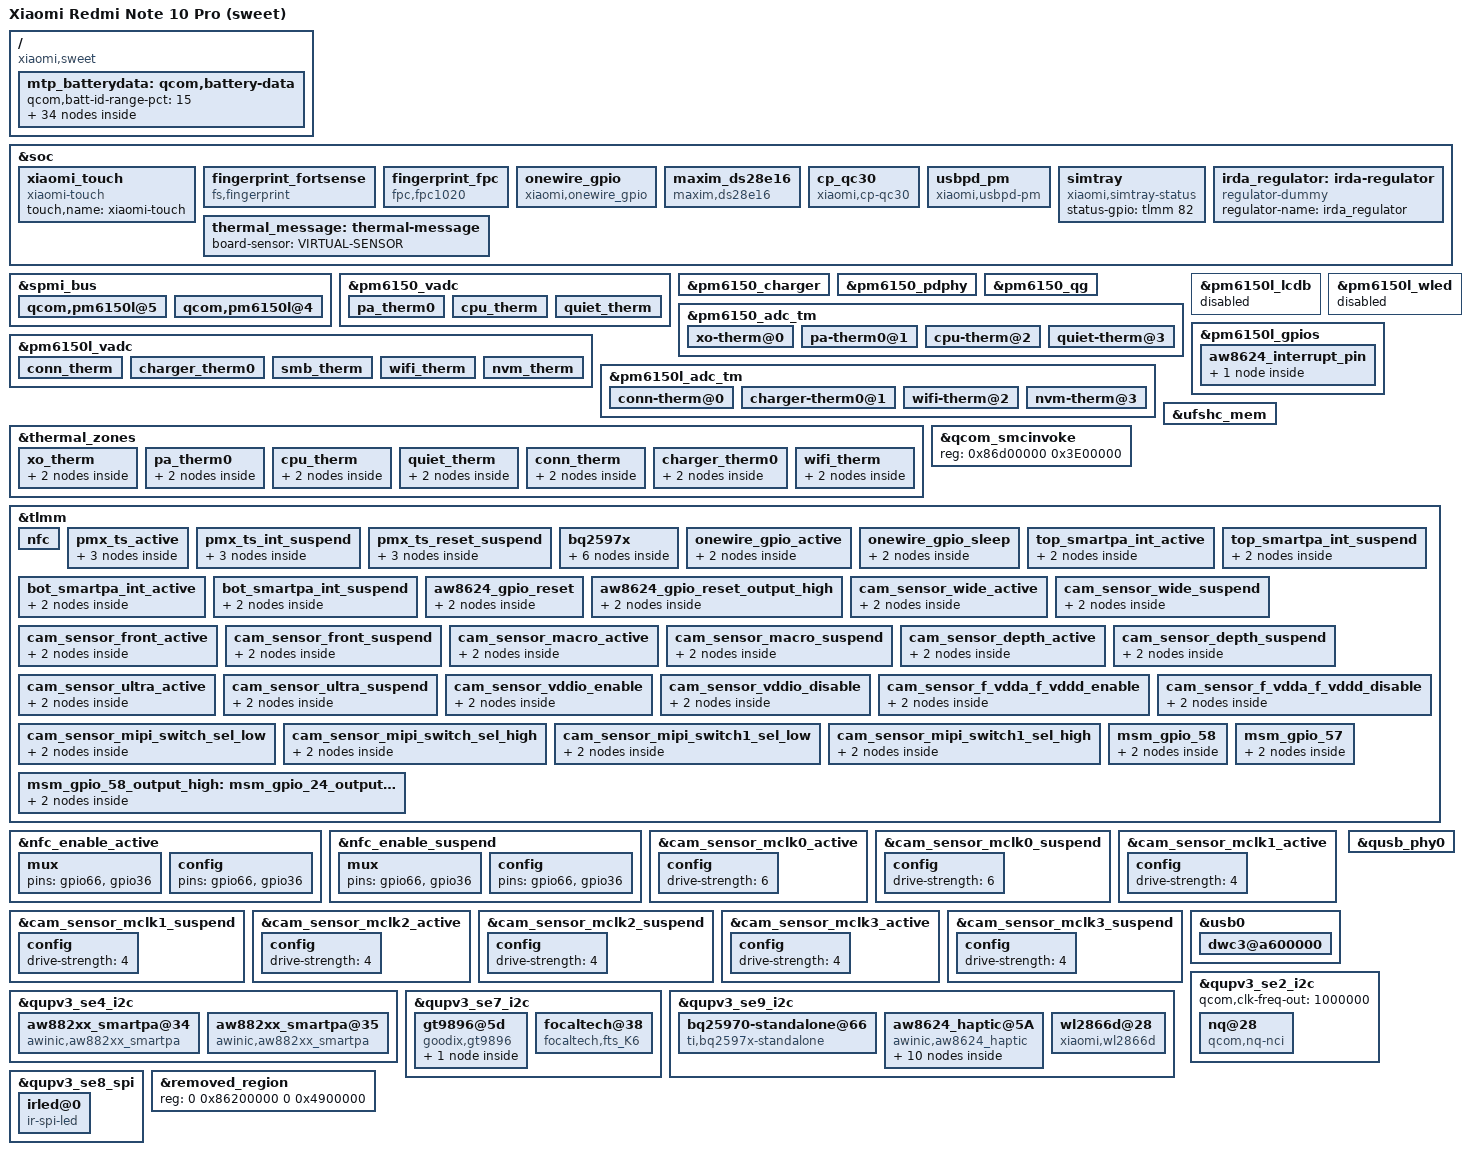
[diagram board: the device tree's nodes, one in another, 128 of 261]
/dts-v1/;

/* Generated by dtsplit.py (tools-sdmmagpie) from the 4.14 sweet files and the 6.1 violet DT. */

#include "xiaomi-sdmmagpie-common.dtsi"

/ {
	/* MERGE model: 4.14 target has "SWEET" */
	/* MERGE compatible: 4.14 target has "qcom,sdmmagpie-qrd", "qcom,sdmmagpie", "qcom,qrd" */
	model = "Xiaomi Redmi Note 10 Pro (sweet)";
	compatible = "xiaomi,sweet", "qcom,sdmmagpie";
	qcom,board-id = <46 0>;

	/* sweet battery profiles (4.14 sweet-sdmmagpie.dtsi) */
	mtp_batterydata: qcom,battery-data {
		qcom,batt-id-range-pct = <15>;

		qcom,04890898_xiaomi_K6_SWBN53_5020mah_FG {
			qcom,max-voltage-uv = <4450000>;
			qcom,ffc-max-voltage-uv = <4470000>;
			qcom,fg-cc-cv-threshold-uv = <4440000>;
			qcom,fastchg-current-ma = <6000>;
			qcom,jeita-fcc-ranges = <0 50 980000 51 100 2460000 101 150 3440000 151 480 6000000 481 600 2460000>;
			qcom,jeita-fv-ranges = <0 50 4450000 51 100 4450000 101 150 4450000 151 480 4470000 481 600 4100000>;
			qcom,step-chg-ranges = <3001000 4250000 6000000 4250001 4350000 4900000 4350001 4450000 4900000 4450001 4460000 3900000 4460001 4470000 3900000>;
			qcom,nom-batt-capacity-mah = <5020>;
			qcom,batt-id-kohm = <100>;
			qcom,battery-beta = <4250>;
			qcom,battery-therm-kohm = <100>;
			qcom,battery-type = "K6_sunwoda_5020mah";
			qcom,qg-batt-profile-ver = <100>;
			mi,six-pin-battery;
			mi,use-bq-pump;
			mi,step-chg-hysteresis = <5000>;

			qcom,fcc1-temp-lut {
				qcom,lut-col-legend = <0 10 25 40 50>;
				qcom,lut-data = <4757 4891 4997 5055 5078>;
			};

			qcom,fcc2-temp-lut {
				qcom,lut-col-legend = <(-10) 0 10 25 40 50>;
				qcom,lut-data = <4968 4967 5004 5018 5018 5015>;
			};

			qcom,pc-temp-v1-lut {
				qcom,lut-col-legend = <0 10 25 40 50>;
				qcom,lut-row-legend = <10000 9800 9600 9400 9200>, <9000 8800 8600 8400 8200>, <8000 7800 7600 7400 7200>, <7000 6800 6600 6400 6200>, <6000 5800 5600 5400 5200>, <5000 4800 4600 4400 4200>, <4000 3800 3600 3400 3200>, <3000 2800 2600 2400 2200>, <2000 1800 1600 1400 1200>, <1000 900 800 700 600>, <500 400 300 200 100>, <0>;
				qcom,lut-data = <44123 44255 44335 44363 44372>, <43931 44073 44168 44204 44214>, <43728 43883 43990 44030 44042>, <43515 43686 43802 43846 43859>, <43289 43478 43604 43651 43667>, <43055 43250 43393 43444 43463>, <42819 43012 43164 43222 43245>, <42578 42773 42925 42984 43012>, <42339 42529 42684 42743 42771>, <42102 42287 42438 42498 42528>, <41870 42049 42194 42253 42282>, <41643 41813 41951 42011 42040>, <41421 41583 41713 41772 41800>, <41206 41357 41480 41537 41564>, <41001 41137 41253 41305 41332>, <40803 40929 41033 41079 41105>, <40600 40727 40819 40860 40885>, <40386 40528 40611 40649 40671>, <40177 40340 40414 40446 40465>, <39990 40138 40230 40258 40274>, <39824 39879 40021 40062 40082>, <39642 39574 39731 39812 39844>, <39397 39337 39435 39523 39560>, <39137 39172 39244 39303 39330>, <38966 39038 39106 39150 39172>, <38857 38927 38982 39018 39038>, <38771 38834 38865 38887 38902>, <38696 38747 38756 38763 38771>, <38633 38661 38652 38650 38654>, <38573 38578 38551 38547 38553>, <38513 38500 38459 38453 38460>, <38456 38426 38377 38369 38372>, <38404 38359 38302 38293 38289>, <38355 38303 38234 38220 38209>, <38310 38254 38172 38149 38132>, <38268 38205 38115 38079 38056>, <38229 38161 38063 38014 37979>, <38177 38111 38011 37949 37901>, <38096 38034 37937 37867 37810>, <37993 37930 37833 37759 37699>, <37877 37813 37715 37637 37573>, <37737 37677 37586 37501 37429>, <37579 37525 37445 37354 37274>, <37404 37345 37280 37195 37114>, <37310 37215 37153 37077 37010>, <37223 37142 37078 37015 36950>, <37190 37123 37057 36994 36929>, <37160 37097 37042 36977 36914>, <37123 37067 37012 36942 36865>, <37016 36929 36885 36758 36651>, <36677 36555 36525 36382 36267>, <36194 36059 36046 35890 35773>, <35582 35420 35428 35255 35133>, <34752 34540 34583 34385 34252>, <33439 33113 33256 32985 32824>, <30000 30000 30000 30000 30000>;
			};

			qcom,pc-temp-v2-lut {
				qcom,lut-col-legend = <(-10) 0 10 25 40 50>;
				qcom,lut-row-legend = <10000 9800 9600 9400 9200 9000>, <8800 8600 8400 8200 8000 7800>, <7600 7400 7200 7000 6800 6600>, <6400 6200 6000 5800 5600 5400>, <5200 5000 4800 4600 4400 4200>, <4000 3800 3600 3400 3200 3000>, <2800 2600 2400 2200 2000 1800>, <1600 1400 1200 1000 900 800>, <700 600 500 400 300 200>, <100 0>;
				qcom,lut-data = <44365 44345 44335 44330 44290 44270>, <44073 44080 44114 44124 44081 44062>, <43806 43830 43898 43919 43873 43855>, <43569 43600 43687 43715 43668 43650>, <43363 43390 43485 43514 43465 43448>, <43153 43176 43274 43304 43255 43238>, <42920 42937 43041 43076 43028 43012>, <42676 42687 42796 42836 42791 42777>, <42428 42434 42551 42595 42552 42539>, <42172 42175 42303 42349 42307 42294>, <41922 41925 42057 42103 42064 42051>, <41689 41696 41814 41861 41823 41810>, <41466 41478 41575 41620 41584 41573>, <41248 41258 41341 41385 41351 41340>, <41041 41035 41111 41156 41123 41112>, <40815 40815 40890 40932 40901 40890>, <40509 40604 40686 40715 40685 40676>, <40151 40395 40485 40503 40474 40467>, <39863 40158 40257 40297 40272 40267>, <39643 39870 39993 40100 40082 40078>, <39440 39583 39731 39886 39876 39874>, <39231 39336 39487 39617 39611 39613>, <39025 39111 39256 39334 39330 39335>, <38833 38912 39062 39121 39119 39126>, <38649 38737 38896 38952 38954 38962>, <38484 38577 38748 38806 38809 38817>, <38343 38414 38613 38676 38680 38685>, <38217 38256 38490 38561 38564 38566>, <38125 38136 38377 38450 38456 38457>, <38062 38045 38273 38345 38355 38357>, <38009 37975 38176 38248 38263 38264>, <37955 37928 38082 38159 38180 38179>, <37903 37893 37995 38078 38102 38099>, <37847 37858 37917 38003 38017 38009>, <37789 37821 37846 37934 37929 37911>, <37727 37780 37784 37861 37833 37807>, <37661 37727 37733 37770 37726 37689>, <37591 37659 37688 37672 37613 37564>, <37512 37580 37625 37578 37510 37456>, <37414 37485 37536 37488 37416 37362>, <37309 37376 37430 37390 37316 37262>, <37211 37256 37302 37276 37200 37143>, <37115 37122 37160 37152 37077 37017>, <37028 37010 37026 37014 36942 36878>, <36947 36911 36924 36926 36865 36806>, <36859 36810 36861 36887 36838 36781>, <36807 36748 36830 36873 36826 36768>, <36742 36670 36791 36851 36802 36742>, <36646 36565 36715 36802 36737 36655>, <36481 36407 36531 36631 36462 36340>, <36210 36170 36160 36217 36014 35882>, <35788 35773 35605 35676 35440 35296>, <35176 35186 34846 34962 34686 34517>, <34277 34354 33804 33970 33604 33420>, <32804 32994 31968 32363 31950 31600>, <28324 29464 26656 28793 27050 26674>;
			};

			qcom,pc-temp-z1-lut {
				qcom,lut-col-legend = <0 10 25 40 50>;
				qcom,lut-row-legend = <10000 9800 9600 9400 9200>, <9000 8800 8600 8400 8200>, <8000 7800 7600 7400 7200>, <7000 6800 6600 6400 6200>, <6000 5800 5600 5400 5200>, <5000 4800 4600 4400 4200>, <4000 3800 3600 3400 3200>, <3000 2800 2600 2400 2200>, <2000 1800 1600 1400 1200>, <1000 900 800 700 600>, <500 400 300 200 100>, <0>;
				qcom,lut-data = <12324 11754 11200 10935 10845>, <12334 11788 11232 10974 10885>, <12340 11798 11251 10987 10898>, <12343 11797 11254 10990 10904>, <12344 11792 11250 10989 10904>, <12343 11780 11245 10986 10902>, <12341 11764 11238 10982 10900>, <12339 11751 11228 10978 10897>, <12334 11738 11220 10975 10895>, <12302 11726 11211 10973 10895>, <12260 11713 11206 10971 10895>, <12243 11700 11203 10970 10894>, <12236 11696 11201 10969 10894>, <12229 11694 11200 10968 10893>, <12215 11693 11199 10968 10893>, <12198 11691 11199 10968 10894>, <12185 11689 11198 10969 10894>, <12171 11687 11198 10969 10896>, <12160 11680 11198 10969 10897>, <12158 11673 11199 10970 10898>, <12158 11673 11199 10970 10899>, <12159 11675 11199 10971 10900>, <12160 11677 11200 10971 10900>, <12164 11683 11201 10972 10901>, <12166 11689 11203 10973 10903>, <12164 11689 11205 10975 10906>, <12164 11687 11208 10978 10908>, <12171 11685 11211 10981 10911>, <12180 11688 11215 10984 10914>, <12186 11692 11219 10987 10916>, <12186 11694 11223 10991 10919>, <12186 11696 11227 10994 10922>, <12188 11699 11231 10997 10926>, <12199 11703 11236 11001 10930>, <12210 11708 11242 11006 10933>, <12215 11713 11247 11010 10937>, <12217 11717 11251 11014 10941>, <12218 11723 11254 11018 10944>, <12235 11733 11259 11021 10948>, <12256 11750 11267 11025 10951>, <12261 11762 11273 11029 10953>, <12266 11769 11278 11032 10956>, <12275 11780 11282 11034 10958>, <12297 11806 11288 11037 10960>, <12318 11806 11299 11042 10963>, <12300 11798 11304 11045 10965>, <12309 11804 11304 11045 10965>, <12302 11800 11302 11046 10967>, <12292 11794 11304 11048 10969>, <12315 11799 11316 11054 10973>, <12330 11819 11321 11058 10977>, <12351 11835 11328 11065 10983>, <12575 11865 11334 11071 10989>, <12356 11859 11348 11083 11000>, <12356 11859 11348 11083 11000>, <12356 11859 11348 11083 11000>;
			};

			qcom,pc-temp-z2-lut {
				qcom,lut-col-legend = <0 10 25 40 50>;
				qcom,lut-row-legend = <10000 9800 9600 9400 9200>, <9000 8800 8600 8400 8200>, <8000 7800 7600 7400 7200>, <7000 6800 6600 6400 6200>, <6000 5800 5600 5400 5200>, <5000 4800 4600 4400 4200>, <4000 3800 3600 3400 3200>, <3000 2800 2600 2400 2200>, <2000 1800 1600 1400 1200>, <1000 900 800 700 600>, <500 400 300 200 100>, <0>;
				qcom,lut-data = <11147 10298 10813 10403 10266>, <10909 10780 10834 10509 10460>, <10730 10802 10841 10581 10424>, <10641 10776 10830 10608 10395>, <10587 10745 10783 10583 10386>, <10546 10700 10731 10541 10371>, <10512 10653 10678 10508 10361>, <10483 10620 10628 10477 10344>, <10468 10592 10591 10453 10329>, <10462 10580 10560 10436 10325>, <10458 10581 10549 10422 10322>, <10460 10583 10571 10410 10296>, <10477 10592 10604 10400 10201>, <10501 10637 10622 10389 10144>, <10532 10684 10634 10364 10148>, <10574 10707 10648 10342 10156>, <10614 10726 10669 10328 10168>, <10655 10745 10693 10294 10193>, <10690 10771 10714 10288 10221>, <10715 10788 10733 10312 10250>, <10735 10788 10758 10353 10280>, <10744 10784 10810 10461 10315>, <10729 10776 10861 10650 10353>, <10700 10745 10850 10706 10389>, <10688 10713 10779 10587 10416>, <10685 10721 10740 10473 10444>, <10683 10768 10820 10562 10491>, <10688 10808 10927 10785 10555>, <10706 10831 10937 10848 10572>, <10723 10847 10906 10706 10420>, <10736 10845 10868 10550 10242>, <10747 10823 10810 10486 10188>, <10757 10805 10755 10442 10151>, <10765 10802 10749 10420 10147>, <10774 10800 10761 10433 10194>, <10786 10802 10779 10463 10264>, <10801 10817 10820 10539 10334>, <10820 10841 10879 10671 10414>, <10853 10875 10938 10754 10475>, <10893 10921 11007 10816 10516>, <10932 10955 11045 10862 10563>, <10970 10972 11050 10890 10673>, <11044 10998 11054 10907 10788>, <11164 11062 11066 10897 10808>, <11003 11393 11124 10779 10686>, <10822 11490 11148 10618 10471>, <10770 11534 11095 10612 10452>, <10764 11519 11081 10613 10484>, <10775 11621 11133 10758 10636>, <10709 11763 11195 10695 10552>, <10682 11824 11088 10412 10256>, <10511 11686 10933 10331 10191>, <10398 11512 10852 10258 10146>, <10181 11221 10771 10226 10062>, <10181 11221 10771 10226 10062>, <10181 11221 10771 10226 10062>;
			};

			qcom,pc-temp-z3-lut {
				qcom,lut-col-legend = <0 10 25 40 50>;
				qcom,lut-row-legend = <10000 9800 9600 9400 9200>, <9000 8800 8600 8400 8200>, <8000 7800 7600 7400 7200>, <7000 6800 6600 6400 6200>, <6000 5800 5600 5400 5200>, <5000 4800 4600 4400 4200>, <4000 3800 3600 3400 3200>, <3000 2800 2600 2400 2200>, <2000 1800 1600 1400 1200>, <1000 900 800 700 600>, <500 400 300 200 100>, <0>;
				qcom,lut-data = <19535 19404 19340 19325 19325>, <19607 19476 19387 19345 19335>, <19665 19515 19422 19374 19358>, <19702 19542 19439 19394 19380>, <19729 19562 19450 19404 19389>, <19749 19579 19457 19412 19395>, <19764 19590 19464 19420 19402>, <19777 19591 19469 19428 19409>, <19784 19590 19469 19431 19412>, <19789 19588 19468 19428 19411>, <19793 19585 19466 19422 19407>, <19792 19579 19459 19416 19403>, <19787 19572 19450 19408 19396>, <19780 19561 19441 19401 19390>, <19771 19551 19432 19396 19386>, <19759 19546 19425 19392 19382>, <19749 19542 19421 19388 19379>, <19741 19537 19418 19384 19376>, <19733 19528 19415 19380 19373>, <19728 19522 19411 19375 19368>, <19724 19536 19409 19372 19364>, <19722 19577 19424 19374 19363>, <19737 19593 19444 19379 19364>, <19762 19574 19440 19380 19364>, <19768 19546 19411 19363 19359>, <19757 19530 19395 19347 19353>, <19742 19517 19395 19366 19366>, <19730 19511 19395 19412 19408>, <19717 19518 19402 19428 19426>, <19710 19530 19428 19426 19416>, <19707 19540 19444 19422 19402>, <19705 19550 19445 19415 19393>, <19703 19556 19445 19403 19386>, <19701 19553 19442 19392 19378>, <19698 19548 19435 19384 19369>, <19694 19544 19428 19377 19361>, <19689 19540 19420 19373 19358>, <19683 19536 19413 19369 19355>, <19675 19531 19411 19367 19354>, <19665 19524 19409 19366 19353>, <19655 19517 19409 19365 19353>, <19644 19512 19410 19374 19363>, <19627 19505 19410 19385 19379>, <19596 19494 19405 19383 19380>, <19344 19446 19384 19371 19369>, <19305 19424 19374 19344 19344>, <19298 19410 19373 19342 19340>, <19295 19410 19362 19340 19330>, <19294 19367 19355 19325 19322>, <19293 19383 19349 19341 19334>, <19297 19306 19356 19364 19360>, <19297 19301 19346 19367 19360>, <19299 19297 19343 19369 19362>, <19304 19290 19344 19357 19360>, <19304 19290 19344 19357 19360>, <19304 19290 19344 19357 19360>;
			};

			qcom,pc-temp-z4-lut {
				qcom,lut-col-legend = <0 10 25 40 50>;
				qcom,lut-row-legend = <10000 9800 9600 9400 9200>, <9000 8800 8600 8400 8200>, <8000 7800 7600 7400 7200>, <7000 6800 6600 6400 6200>, <6000 5800 5600 5400 5200>, <5000 4800 4600 4400 4200>, <4000 3800 3600 3400 3200>, <3000 2800 2600 2400 2200>, <2000 1800 1600 1400 1200>, <1000 900 800 700 600>, <500 400 300 200 100>, <0>;
				qcom,lut-data = <15538 15236 14999 14882 14826>, <15517 15308 14998 14890 14847>, <15484 15289 14996 14881 14843>, <15436 15206 14982 14869 14836>, <15341 15127 14939 14848 14822>, <15239 15065 14898 14822 14799>, <15164 15009 14867 14799 14779>, <15098 14964 14840 14776 14761>, <15042 14927 14817 14758 14745>, <14993 14895 14796 14741 14730>, <14951 14867 14779 14729 14719>, <14918 14843 14765 14725 14715>, <14891 14822 14754 14723 14714>, <14868 14803 14748 14720 14713>, <14845 14789 14745 14716 14709>, <14825 14778 14741 14711 14705>, <14815 14771 14734 14707 14700>, <14812 14769 14726 14702 14695>, <14809 14772 14723 14698 14691>, <14808 14779 14721 14696 14690>, <14806 14793 14721 14695 14689>, <14806 14823 14756 14717 14706>, <14832 14852 14810 14779 14771>, <14879 14886 14842 14816 14803>, <14897 14911 14866 14833 14803>, <14901 14913 14875 14842 14802>, <14902 14909 14868 14817 14782>, <14899 14902 14853 14753 14724>, <14885 14881 14830 14721 14698>, <14869 14851 14790 14711 14697>, <14853 14826 14760 14705 14696>, <14836 14803 14744 14702 14694>, <14821 14787 14733 14700 14689>, <14809 14780 14729 14699 14687>, <14799 14775 14728 14701 14689>, <14790 14772 14727 14702 14690>, <14782 14769 14728 14702 14691>, <14776 14768 14729 14702 14691>, <14773 14769 14732 14704 14693>, <14770 14772 14741 14715 14703>, <14763 14772 14746 14724 14711>, <14750 14760 14738 14714 14703>, <14738 14745 14727 14701 14690>, <14728 14734 14724 14701 14691>, <14864 14704 14707 14694 14686>, <14886 14685 14679 14684 14671>, <14885 14685 14667 14672 14662>, <14879 14674 14658 14656 14651>, <14877 14714 14653 14651 14640>, <14876 14700 14669 14659 14663>, <14885 14807 14691 14662 14662>, <14891 14815 14704 14663 14666>, <14894 14824 14710 14664 14666>, <14902 14834 14711 14676 14668>, <14902 14834 14711 14676 14668>, <14902 14834 14711 14676 14668>;
			};

			qcom,pc-temp-z5-lut {
				qcom,lut-col-legend = <0 10 25 40 50>;
				qcom,lut-row-legend = <10000 9800 9600 9400 9200>, <9000 8800 8600 8400 8200>, <8000 7800 7600 7400 7200>, <7000 6800 6600 6400 6200>, <6000 5800 5600 5400 5200>, <5000 4800 4600 4400 4200>, <4000 3800 3600 3400 3200>, <3000 2800 2600 2400 2200>, <2000 1800 1600 1400 1200>, <1000 900 800 700 600>, <500 400 300 200 100>, <0>;
				qcom,lut-data = <13138 12985 13500 13875 14350>, <14188 14730 15281 14900 14974>, <15064 15622 16528 16568 16703>, <15704 16188 17034 17785 18361>, <16151 16719 17308 18333 19126>, <16599 17280 17596 18800 19710>, <17197 17811 17962 19612 20554>, <17922 18291 18343 20794 21826>, <18741 18718 18705 21684 23014>, <19782 19193 19061 22330 24035>, <20934 19779 19446 22747 24854>, <22002 20452 19999 22594 24857>, <23080 21208 20452 21982 24146>, <24181 22098 20426 21619 23693>, <25218 22983 20150 21870 23812>, <26272 23907 20016 22240 24088>, <27706 24767 20581 22501 24565>, <30434 24946 21453 23140 25628>, <32812 24360 21919 23653 26449>, <33106 23805 22184 24222 26902>, <32880 30080 22714 24723 27195>, <32794 47031 27829 24897 26789>, <39083 53991 34105 24895 24828>, <49798 43999 32902 24375 22514>, <52398 30996 24374 20036 19181>, <46447 25969 18921 16014 16396>, <39443 23023 17913 17572 18649>, <35950 21945 17369 22105 26398>, <33330 22522 17830 24992 29633>, <32327 23813 20369 26763 28113>, <33013 25771 23079 27725 26472>, <34396 29549 25391 27389 26462>, <35900 32929 27534 26549 26917>, <37880 34851 29079 26204 26999>, <39817 36306 30405 26632 26536>, <41246 37130 30963 27048 26135>, <42463 37698 30497 27095 26369>, <43547 37989 29631 27053 26949>, <44647 37400 28840 26492 26904>, <45538 35880 27818 24714 24564>, <45911 34979 27295 23458 22578>, <45946 34505 27348 25800 26567>, <45435 34328 27397 28818 32474>, <42949 34226 26145 27919 32544>, <17074 33443 25068 25279 28665>, <13468 31192 25892 19940 20952>, <13204 26073 27431 20700 21130>, <13137 27849 26089 23250 21487>, <13108 22125 25989 21722 23386>, <13164 21237 21541 25221 24234>, <13244 13620 18391 23514 24384>, <13066 13274 16300 22702 22231>, <12952 12953 15517 21271 20649>, <12790 12581 15188 17110 17819>, <12790 12581 15188 17110 17819>, <12790 12581 15188 17110 17819>;
			};

			qcom,pc-temp-z6-lut {
				qcom,lut-col-legend = <0 10 25 40 50>;
				qcom,lut-row-legend = <10000 9800 9600 9400 9200>, <9000 8800 8600 8400 8200>, <8000 7800 7600 7400 7200>, <7000 6800 6600 6400 6200>, <6000 5800 5600 5400 5200>, <5000 4800 4600 4400 4200>, <4000 3800 3600 3400 3200>, <3000 2800 2600 2400 2200>, <2000 1800 1600 1400 1200>, <1000 900 800 700 600>, <500 400 300 200 100>, <0>;
				qcom,lut-data = <15508 14992 14667 14556 14518>, <15504 15059 14699 14580 14542>, <15492 15056 14716 14594 14556>, <15471 15027 14714 14598 14563>, <15422 14997 14702 14594 14561>, <15366 14969 14688 14588 14556>, <15324 14942 14677 14582 14552>, <15286 14916 14667 14577 14548>, <15252 14892 14656 14571 14544>, <15221 14871 14645 14562 14538>, <15193 14852 14635 14554 14531>, <15168 14835 14625 14547 14525>, <15146 14819 14615 14542 14521>, <15125 14803 14608 14537 14517>, <15103 14790 14601 14532 14513>, <15082 14782 14595 14528 14509>, <15067 14775 14589 14523 14505>, <15055 14771 14584 14518 14501>, <15047 14769 14581 14514 14497>, <15044 14767 14578 14511 14494>, <15042 14780 14577 14509 14491>, <15041 14816 14603 14521 14498>, <15061 14833 14637 14552 14527>, <15095 14834 14641 14563 14540>, <15105 14835 14640 14562 14539>, <15101 14833 14637 14560 14536>, <15096 14826 14633 14558 14534>, <15089 14818 14629 14556 14533>, <15078 14813 14625 14553 14531>, <15068 14808 14621 14549 14526>, <15060 14804 14617 14544 14519>, <15053 14800 14612 14538 14514>, <15047 14797 14608 14532 14509>, <15043 14794 14604 14527 14504>, <15039 14791 14601 14524 14500>, <15036 14790 14598 14522 14497>, <15033 14788 14595 14519 14495>, <15032 14788 14593 14516 14493>, <15034 14789 14593 14516 14493>, <15036 14791 14598 14520 14496>, <15036 14791 14600 14524 14500>, <15034 14787 14598 14525 14503>, <15031 14782 14595 14526 14506>, <15023 14777 14592 14525 14507>, <14967 14749 14576 14516 14499>, <14956 14731 14559 14498 14480>, <14952 14724 14554 14492 14475>, <14950 14721 14545 14484 14464>, <14953 14719 14539 14473 14455>, <14958 14727 14545 14486 14471>, <14970 14737 14560 14502 14488>, <14979 14742 14563 14506 14492>, <14989 14750 14567 14510 14496>, <15008 14760 14572 14512 14499>, <15008 14760 14572 14512 14499>, <15008 14760 14572 14512 14499>;
			};

			qcom,pc-temp-y1-lut {
				qcom,lut-col-legend = <(-10) 0 10 25 40 50>;
				qcom,lut-row-legend = <10000 9800 9600 9400 9200 9000>, <8800 8600 8400 8200 8000 7800>, <7600 7400 7200 7000 6800 6600>, <6400 6200 6000 5800 5600 5400>, <5200 5000 4800 4600 4400 4200>, <4000 3800 3600 3400 3200 3000>, <2800 2600 2400 2200 2000 1800>, <1600 1400 1200 1000 900 800>, <700 600 500 400 300 200>, <100 0>;
				qcom,lut-data = <5992 5573 5288 5013 4864 4813>, <5980 5573 5297 5013 4863 4813>, <5967 5573 5304 5012 4862 4812>, <5955 5574 5308 5010 4861 4812>, <5945 5575 5310 5009 4860 4811>, <5941 5576 5311 5007 4859 4810>, <5943 5579 5308 5004 4859 4810>, <5946 5583 5303 5002 4858 4809>, <5949 5584 5299 5000 4857 4809>, <5954 5578 5294 4998 4856 4808>, <5958 5573 5290 4997 4855 4808>, <5957 5573 5287 4996 4854 4807>, <5954 5574 5284 4996 4853 4807>, <5954 5573 5284 4995 4852 4806>, <5960 5567 5284 4993 4852 4806>, <5969 5562 5285 4992 4852 4806>, <5979 5572 5284 4992 4852 4805>, <5990 5591 5283 4992 4852 4805>, <5993 5597 5283 4993 4852 4805>, <5988 5586 5285 4994 4852 4806>, <5983 5577 5287 4995 4852 4807>, <5979 5577 5285 4996 4854 4808>, <5968 5579 5282 4996 4856 4808>, <5964 5579 5282 4997 4857 4809>, <5964 5581 5286 4999 4857 4811>, <5962 5583 5289 5002 4858 4812>, <5958 5582 5288 5003 4858 4813>, <5950 5577 5285 5005 4860 4815>, <5945 5572 5286 5007 4861 4816>, <5941 5573 5292 5009 4863 4818>, <5937 5575 5296 5012 4865 4820>, <5935 5573 5297 5013 4867 4821>, <5934 5568 5296 5014 4868 4822>, <5933 5566 5297 5016 4870 4823>, <5929 5569 5303 5018 4872 4824>, <5924 5572 5307 5020 4873 4826>, <5921 5569 5305 5021 4874 4827>, <5916 5560 5300 5021 4875 4828>, <5912 5553 5299 5022 4876 4829>, <5905 5548 5301 5025 4877 4831>, <5899 5543 5304 5027 4878 4832>, <5899 5542 5309 5029 4879 4833>, <5899 5544 5315 5032 4882 4835>, <5896 5546 5323 5035 4884 4837>, <5904 5549 5324 5040 4888 4839>, <5979 5564 5333 5045 4888 4840>, <5951 5571 5341 5044 4888 4840>, <5952 5581 5332 5048 4888 4840>, <5945 5587 5481 5042 4888 4841>, <5965 5588 5369 5042 4889 4841>, <5969 5590 5336 5048 4890 4843>, <5957 5583 5350 5052 4894 4847>, <5945 5585 5346 5059 4899 4851>, <6007 5593 5348 5069 4907 4859>, <6007 5593 5348 5069 4907 4859>, <6007 5593 5348 5069 4907 4859>;
			};

			qcom,pc-temp-y2-lut {
				qcom,lut-col-legend = <(-10) 0 10 25 40 50>;
				qcom,lut-row-legend = <10000 9800 9600 9400 9200 9000>, <8800 8600 8400 8200 8000 7800>, <7600 7400 7200 7000 6800 6600>, <6400 6200 6000 5800 5600 5400>, <5200 5000 4800 4600 4400 4200>, <4000 3800 3600 3400 3200 3000>, <2800 2600 2400 2200 2000 1800>, <1600 1400 1200 1000 900 800>, <700 600 500 400 300 200>, <100 0>;
				qcom,lut-data = <10597 10766 11398 11596 11200 11128>, <10630 10803 11387 11536 11142 11076>, <10709 10871 11372 11472 11082 11014>, <10803 10947 11354 11411 11024 10951>, <10883 11010 11334 11358 10973 10897>, <10919 11037 11311 11321 10933 10860>, <10919 11035 11280 11296 10899 10838>, <10919 11030 11250 11277 10872 10820>, <10919 11031 11241 11258 10859 10802>, <10921 11044 11237 11237 10852 10777>, <10925 11057 11236 11226 10847 10760>, <10957 11056 11250 11233 10843 10756>, <11022 11048 11282 11249 10838 10755>, <11076 11062 11315 11266 10852 10756>, <11140 11154 11351 11291 10929 10758>, <11187 11244 11394 11325 10989 10760>, <11200 11291 11463 11378 11001 10762>, <11209 11345 11537 11452 11010 10765>, <11221 11362 11565 11545 11063 10804>, <11246 11371 11576 11682 11262 10990>, <11274 11382 11581 11757 11389 11112>, <11295 11394 11586 11702 11342 11102>, <11313 11411 11598 11615 11262 11086>, <11317 11427 11610 11603 11237 11083>, <11287 11451 11634 11639 11235 11086>, <11238 11470 11657 11679 11248 11090>, <11075 11448 11672 11709 11310 11113>, <10719 11382 11687 11739 11397 11159>, <10527 11345 11710 11771 11426 11221>, <10189 11352 11752 11808 11422 11330>, <9834 11357 11779 11840 11431 11423>, <9767 11313 11757 11864 11522 11480>, <9741 11200 11712 11882 11641 11524>, <9721 11056 11692 11890 11671 11546>, <9703 10726 11686 11894 11675 11576>, <9690 10374 11678 11891 11673 11580>, <9683 10177 11641 11844 11569 11503>, <9679 9874 11565 11766 11411 11383>, <9675 9716 11486 11728 11385 11311>, <9672 9693 11401 11709 11413 11262>, <9670 9680 11303 11690 11431 11227>, <9668 9673 11180 11664 11403 11208>, <9667 9669 11041 11627 11342 11185>, <9666 9666 10901 11523 11174 11068>, <9664 9664 10767 11404 11005 10901>, <9663 9663 10778 11336 10983 10832>, <9662 9663 10771 11319 11048 10840>, <9662 9662 10738 11314 11086 10887>, <9661 9661 10723 11320 11144 10873>, <9659 9660 10708 11349 11003 10834>, <9658 9659 10638 11299 10876 10763>, <9656 9658 10491 11190 10825 10710>, <9653 9657 9948 11078 10781 10622>, <9650 9655 9722 10982 10651 10446>, <9650 9655 9722 10982 10651 10446>, <9650 9655 9722 10982 10651 10446>;
			};

			qcom,pc-temp-y3-lut {
				qcom,lut-col-legend = <(-10) 0 10 25 40 50>;
				qcom,lut-row-legend = <10000 9800 9600 9400 9200 9000>, <8800 8600 8400 8200 8000 7800>, <7600 7400 7200 7000 6800 6600>, <6400 6200 6000 5800 5600 5400>, <5200 5000 4800 4600 4400 4200>, <4000 3800 3600 3400 3200 3000>, <2800 2600 2400 2200 2000 1800>, <1600 1400 1200 1000 900 800>, <700 600 500 400 300 200>, <100 0>;
				qcom,lut-data = <13439 13416 13326 13287 13280 13279>, <13446 13419 13330 13289 13281 13279>, <13458 13422 13334 13291 13281 13280>, <13473 13425 13337 13292 13282 13280>, <13485 13427 13340 13294 13282 13281>, <13491 13429 13343 13295 13283 13282>, <13492 13430 13344 13295 13284 13283>, <13493 13431 13345 13296 13285 13284>, <13492 13432 13347 13297 13287 13285>, <13487 13432 13349 13298 13288 13285>, <13483 13432 13350 13298 13288 13285>, <13495 13439 13350 13298 13289 13286>, <13517 13451 13349 13298 13289 13287>, <13519 13450 13348 13299 13290 13288>, <13474 13410 13346 13303 13294 13289>, <13437 13377 13343 13305 13297 13290>, <13440 13385 13339 13304 13296 13291>, <13448 13405 13335 13303 13294 13292>, <13450 13411 13333 13304 13294 13293>, <13439 13398 13332 13306 13298 13295>, <13425 13383 13331 13308 13300 13296>, <13415 13375 13328 13304 13295 13291>, <13407 13369 13323 13296 13286 13284>, <13399 13362 13321 13292 13282 13282>, <13392 13356 13319 13289 13281 13281>, <13385 13350 13318 13288 13280 13281>, <13369 13346 13317 13289 13281 13280>, <13344 13343 13317 13290 13281 13280>, <13335 13339 13316 13290 13281 13281>, <13343 13328 13314 13289 13280 13282>, <13355 13320 13313 13289 13279 13282>, <13369 13321 13313 13289 13280 13282>, <13386 13331 13312 13289 13281 13281>, <13406 13340 13312 13289 13281 13282>, <13428 13348 13312 13290 13282 13282>, <13454 13357 13312 13290 13282 13283>, <13485 13372 13313 13290 13281 13282>, <13522 13395 13317 13289 13280 13280>, <13560 13422 13320 13289 13280 13280>, <13599 13454 13322 13289 13282 13281>, <13638 13493 13324 13289 13284 13282>, <13680 13537 13326 13289 13284 13282>, <13724 13588 13328 13289 13284 13282>, <13779 13649 13333 13289 13282 13279>, <13848 13724 13340 13292 13283 13280>, <13923 13794 13345 13297 13291 13288>, <13898 13747 13349 13302 13294 13290>, <13964 13799 13359 13306 13296 13291>, <14050 13848 13371 13309 13296 13290>, <14155 13908 13378 13308 13289 13285>, <14305 13965 13380 13301 13288 13285>, <14563 14041 13388 13305 13290 13288>, <15250 14208 13413 13308 13297 13294>, <17272 14524 13522 13319 13305 13303>, <17272 14524 13522 13319 13305 13303>, <17272 14524 13522 13319 13305 13303>;
			};

			qcom,pc-temp-y4-lut {
				qcom,lut-col-legend = <(-10) 0 10 25 40 50>;
				qcom,lut-row-legend = <10000 9800 9600 9400 9200 9000>, <8800 8600 8400 8200 8000 7800>, <7600 7400 7200 7000 6800 6600>, <6400 6200 6000 5800 5600 5400>, <5200 5000 4800 4600 4400 4200>, <4000 3800 3600 3400 3200 3000>, <2800 2600 2400 2200 2000 1800>, <1600 1400 1200 1000 900 800>, <700 600 500 400 300 200>, <100 0>;
				qcom,lut-data = <16736 16675 16565 16490 16464 16461>, <16778 16733 16596 16491 16465 16463>, <16855 16825 16632 16492 16468 16465>, <16942 16923 16665 16494 16470 16466>, <17015 17003 16689 16496 16472 16467>, <17051 17038 16699 16498 16473 16468>, <17056 17034 16695 16501 16474 16467>, <17058 17024 16686 16504 16475 16467>, <17061 17013 16680 16507 16476 16467>, <17065 16999 16676 16511 16478 16470>, <17068 16989 16674 16516 16481 16472>, <17052 16983 16678 16523 16485 16474>, <17023 16979 16687 16531 16490 16476>, <17027 16991 16698 16537 16493 16479>, <17139 17097 16716 16542 16494 16483>, <17232 17185 16739 16548 16495 16487>, <17145 17164 16779 16564 16504 16492>, <16946 17099 16822 16586 16519 16498>, <16864 17030 16823 16604 16535 16510>, <16848 16946 16768 16624 16557 16530>, <16834 16866 16706 16633 16568 16542>, <16811 16812 16657 16592 16542 16522>, <16778 16769 16615 16525 16499 16488>, <16744 16735 16594 16505 16483 16475>, <16699 16710 16582 16498 16478 16470>, <16668 16685 16576 16496 16476 16467>, <16678 16643 16574 16498 16478 16469>, <16712 16589 16573 16504 16482 16472>, <16736 16570 16573 16509 16488 16476>, <16750 16581 16575 16516 16498 16482>, <16763 16598 16576 16523 16509 16488>, <16774 16611 16571 16530 16518 16498>, <16784 16623 16560 16537 16526 16509>, <16795 16641 16553 16541 16526 16511>, <16808 16677 16546 16545 16523 16508>, <16819 16717 16542 16547 16518 16504>, <16824 16743 16549 16531 16506 16495>, <16827 16771 16565 16504 16490 16484>, <16828 16783 16579 16495 16483 16482>, <16824 16784 16589 16492 16479 16484>, <16819 16783 16599 16491 16477 16485>, <16819 16778 16610 16495 16476 16483>, <16823 16763 16620 16499 16476 16479>, <16832 16764 16625 16491 16462 16458>, <16857 16779 16636 16491 16462 16457>, <16886 16822 16626 16498 16486 16500>, <16851 16807 16636 16511 16516 16535>, <16868 16847 16669 16536 16549 16565>, <16885 16901 16707 16568 16566 16569>, <16896 16932 16730 16553 16495 16483>, <16896 16960 16715 16498 16475 16475>, <16887 16959 16712 16502 16479 16475>, <16948 16952 16773 16513 16479 16475>, <17582 16950 16862 16542 16507 16521>, <17582 16950 16862 16542 16507 16521>, <17582 16950 16862 16542 16507 16521>;
			};

			qcom,pc-temp-y5-lut {
				qcom,lut-col-legend = <(-10) 0 10 25 40 50>;
				qcom,lut-row-legend = <10000 9800 9600 9400 9200 9000>, <8800 8600 8400 8200 8000 7800>, <7600 7400 7200 7000 6800 6600>, <6400 6200 6000 5800 5600 5400>, <5200 5000 4800 4600 4400 4200>, <4000 3800 3600 3400 3200 3000>, <2800 2600 2400 2200 2000 1800>, <1600 1400 1200 1000 900 800>, <700 600 500 400 300 200>, <100 0>;
				qcom,lut-data = <12502 15656 18668 18954 18632 19508>, <13631 16121 18502 18462 18254 19032>, <14991 16578 18303 17976 17670 18585>, <16356 17005 18096 17495 17032 18200>, <17504 17377 17908 17020 16489 17911>, <18207 17670 17764 16551 16194 17752>, <18547 17919 17661 16063 16094 17758>, <18765 18111 17559 15597 16008 17811>, <18752 18125 17423 15241 15891 17631>, <18390 17959 17215 14955 15709 16880>, <18111 17831 16985 14673 15483 16241>, <19283 18413 16586 14288 15118 15985>, <21540 19536 16034 13942 14749 15804>, <21946 19592 15608 13932 14809 15694>, <20039 17364 15203 14194 15477 15759>, <18440 15491 14999 14365 15913 15835>, <19712 17553 15277 14164 15317 15660>, <22546 22098 15984 13848 14383 15419>, <23437 23491 17055 14204 14428 15561>, <22716 22807 19180 16540 15733 16095>, <21993 22180 20753 18489 16959 16753>, <21845 22271 21153 19194 17668 17668>, <21628 22581 21397 19638 18191 18574>, <21358 22773 21527 19498 18114 18691>, <20904 22886 21622 18386 17213 18376>, <20211 22970 21704 17648 16449 17948>, <18121 22813 21778 17989 16268 17191>, <14128 22145 21846 18526 16252 16350>, <12546 21161 21920 18543 16131 16216>, <12537 17691 22017 18056 15502 16352>, <12571 14339 22145 17734 15093 16461>, <12668 14259 22745 17876 15461 16449>, <12877 14920 23708 18230 16229 16469>, <13072 15387 23773 18827 16964 16928>, <13212 15397 22387 20119 17767 18559>, <13359 15269 21056 21138 18498 19638>, <13616 15102 20628 21582 19042 19597>, <14005 14585 20318 21869 19538 19480>, <14174 14305 19796 21649 20172 19692>, <13942 14291 18785 20119 20992 20937>, <13573 14279 17742 18727 21671 22391>, <13309 14210 16866 18099 22207 23927>, <13091 14060 16260 17700 22500 24925>, <13065 14011 16226 17497 19716 19136>, <13078 13961 16075 17255 16976 16903>, <13094 13588 16658 17197 17836 16776>, <13296 13796 16791 18041 17796 16271>, <13442 14017 17249 18525 17289 15973>, <13712 14337 18424 18759 17436 15758>, <13869 15426 19566 19371 17037 16788>, <14001 16296 19205 19446 16958 16357>, <13804 15589 17860 19866 16511 16385>, <12888 14114 14461 19649 19958 18394>, <10792 13215 13585 22446 24524 26331>, <10792 13215 13585 22446 24524 26331>, <10792 13215 13585 22446 24524 26331>;
			};

			qcom,pc-temp-y6-lut {
				qcom,lut-col-legend = <(-10) 0 10 25 40 50>;
				qcom,lut-row-legend = <10000 9800 9600 9400 9200 9000>, <8800 8600 8400 8200 8000 7800>, <7600 7400 7200 7000 6800 6600>, <6400 6200 6000 5800 5600 5400>, <5200 5000 4800 4600 4400 4200>, <4000 3800 3600 3400 3200 3000>, <2800 2600 2400 2200 2000 1800>, <1600 1400 1200 1000 900 800>, <700 600 500 400 300 200>, <100 0>;
				qcom,lut-data = <5609 5384 5142 5017 4986 4979>, <5621 5404 5153 5018 4987 4980>, <5636 5424 5163 5019 4988 4982>, <5651 5442 5171 5021 4989 4983>, <5662 5454 5176 5022 4990 4984>, <5667 5459 5178 5023 4992 4985>, <5666 5456 5176 5024 4993 4986>, <5663 5450 5172 5025 4994 4986>, <5660 5443 5169 5026 4995 4987>, <5655 5436 5167 5028 4996 4988>, <5652 5432 5166 5029 4997 4989>, <5654 5433 5167 5031 4999 4990>, <5657 5436 5167 5033 5000 4991>, <5661 5439 5168 5036 5002 4993>, <5667 5442 5171 5039 5004 4994>, <5671 5444 5174 5043 5007 4996>, <5653 5443 5182 5047 5010 4998>, <5610 5439 5191 5052 5012 5001>, <5589 5431 5191 5057 5017 5005>, <5581 5400 5175 5064 5025 5012>, <5574 5367 5156 5068 5030 5016>, <5566 5348 5140 5053 5018 5006>, <5557 5333 5125 5029 4999 4991>, <5549 5322 5118 5020 4992 4985>, <5540 5315 5114 5017 4990 4983>, <5534 5308 5112 5016 4989 4982>, <5533 5298 5112 5017 4989 4983>, <5536 5288 5112 5019 4991 4984>, <5540 5284 5113 5021 4993 4985>, <5556 5289 5114 5023 4995 4987>, <5581 5298 5114 5025 4998 4990>, <5605 5312 5113 5027 5001 4993>, <5632 5339 5112 5029 5004 4996>, <5663 5370 5111 5031 5005 4996>, <5697 5406 5111 5033 5004 4996>, <5735 5447 5111 5034 5003 4995>, <5774 5492 5116 5029 4999 4992>, <5817 5541 5127 5022 4993 4988>, <5858 5591 5137 5019 4993 4987>, <5895 5641 5148 5019 4993 4989>, <5932 5692 5160 5019 4993 4990>, <5973 5743 5175 5020 4994 4990>, <6016 5796 5194 5022 4994 4988>, <6070 5859 5217 5021 4989 4981>, <6140 5937 5247 5024 4990 4982>, <6220 6020 5246 5030 5003 5000>, <6210 5983 5253 5038 5014 5012>, <6272 6041 5279 5048 5024 5021>, <6351 6102 5307 5059 5030 5021>, <6449 6162 5325 5054 5004 4994>, <6582 6224 5334 5034 4998 4992>, <6805 6294 5371 5039 5002 4995>, <7419 6435 5466 5047 5008 5000>, <9235 6696 5634 5065 5023 5022>, <9235 6696 5634 5065 5023 5022>, <9235 6696 5634 5065 5023 5022>;
			};
		};

		qcom,4890802_xiaomi_K6_NVT_5020mAH_PM7150 {
			qcom,max-voltage-uv = <4450000>;
			qcom,ffc-max-voltage-uv = <4470000>;
			qcom,fg-cc-cv-threshold-uv = <4440000>;
			qcom,fastchg-current-ma = <6000>;
			qcom,jeita-fcc-ranges = <0 50 980000 51 100 2460000 101 150 3440000 151 480 6000000 481 600 2460000>;
			qcom,jeita-fv-ranges = <0 50 4450000 51 100 4450000 101 150 4450000 151 480 4470000 481 600 4100000>;
			qcom,step-chg-ranges = <3001000 4250000 6000000 4250001 4350000 4900000 4350001 4450000 4900000 4450001 4460000 3900000 4460001 4470000 3900000>;
			qcom,nom-batt-capacity-mah = <5020>;
			qcom,batt-id-kohm = <100>;
			qcom,battery-beta = <4250>;
			qcom,battery-therm-kohm = <100>;
			qcom,battery-type = "K6_nvt_5020mah";
			qcom,qg-batt-profile-ver = <100>;
			mi,six-pin-battery;
			mi,use-bq-pump;
			mi,step-chg-hysteresis = <5000>;

			qcom,fcc1-temp-lut {
				qcom,lut-col-legend = <0 10 25 40 50>;
				qcom,lut-data = <4813 4966 5078 5110 5119>;
			};

			qcom,fcc2-temp-lut {
				qcom,lut-col-legend = <(-10) 0 10 25 40 50>;
				qcom,lut-data = <4932 5013 5074 5084 5075 5068>;
			};

			qcom,pc-temp-v1-lut {
				qcom,lut-col-legend = <0 10 25 40 50>;
				qcom,lut-row-legend = <10000 9800 9600 9400 9200>, <9000 8800 8600 8400 8200>, <8000 7800 7600 7400 7200>, <7000 6800 6600 6400 6200>, <6000 5800 5600 5400 5200>, <5000 4800 4600 4400 4200>, <4000 3800 3600 3400 3200>, <3000 2800 2600 2400 2200>, <2000 1800 1600 1400 1200>, <1000 900 800 700 600>, <500 400 300 200 100>, <0>;
				qcom,lut-data = <44092 44235 44334 44366 44375>, <43867 44008 44099 44110 44113>, <43638 43781 43882 43894 43895>, <43406 43557 43666 43688 43693>, <43170 43333 43443 43472 43478>, <42930 43099 43216 43251 43257>, <42690 42857 42979 43021 43028>, <42449 42612 42733 42779 42791>, <42209 42368 42485 42531 42549>, <41975 42123 42238 42286 42305>, <41745 41885 41993 42042 42058>, <41521 41651 41753 41801 41816>, <41301 41423 41519 41563 41577>, <41088 41203 41290 41328 41343>, <40879 40988 41067 41103 41117>, <40674 40778 40851 40883 40897>, <40476 40572 40643 40673 40686>, <40283 40376 40443 40470 40482>, <40096 40197 40254 40277 40287>, <39925 40029 40087 40105 40111>, <39775 39856 39917 39938 39943>, <39629 39679 39688 39726 39736>, <39475 39489 39394 39435 39454>, <39316 39246 39165 39188 39207>, <39147 38968 39015 39038 39055>, <38943 38792 38895 38920 38934>, <38739 38703 38788 38801 38813>, <38608 38635 38694 38685 38694>, <38518 38559 38603 38580 38585>, <38449 38486 38508 38485 38488>, <38399 38419 38422 38401 38401>, <38359 38355 38352 38326 38321>, <38321 38297 38292 38259 38247>, <38286 38246 38235 38195 38178>, <38254 38201 38183 38135 38114>, <38223 38161 38133 38077 38051>, <38196 38128 38087 38019 37985>, <38162 38094 38043 37962 37917>, <38110 38039 37982 37891 37836>, <38040 37954 37892 37795 37733>, <37952 37854 37785 37686 37616>, <37830 37733 37670 37574 37497>, <37690 37592 37538 37447 37367>, <37529 37422 37373 37285 37199>, <37373 37267 37217 37138 37059>, <37238 37155 37107 37048 36986>, <37197 37119 37076 37016 36954>, <37173 37097 37052 36994 36933>, <37135 37075 37035 36975 36912>, <37102 37038 36997 36930 36859>, <37051 36871 36796 36701 36615>, <36839 36437 36365 36267 36183>, <36367 35850 35785 35691 35609>, <35725 35026 34987 34907 34828>, <34649 33597 33736 33689 33622>, <30000 30000 30000 30000 30000>;
			};

			qcom,pc-temp-v2-lut {
				qcom,lut-col-legend = <(-10) 0 10 25 40 50>;
				qcom,lut-row-legend = <10000 9800 9600 9400 9200 9000>, <8800 8600 8400 8200 8000 7800>, <7600 7400 7200 7000 6800 6600>, <6400 6200 6000 5800 5600 5400>, <5200 5000 4800 4600 4400 4200>, <4000 3800 3600 3400 3200 3000>, <2800 2600 2400 2200 2000 1800>, <1600 1400 1200 1000 900 800>, <700 600 500 400 300 200>, <100 0>;
				qcom,lut-data = <44355 44345 44330 44315 44275 44270>, <44042 44031 44046 44041 44005 43997>, <43757 43746 43781 43781 43749 43741>, <43506 43494 43539 43541 43513 43505>, <43290 43275 43320 43320 43295 43289>, <43075 43055 43096 43094 43072 43069>, <42844 42814 42854 42855 42835 42834>, <42605 42566 42606 42611 42593 42592>, <42364 42317 42357 42365 42349 42349>, <42117 42063 42107 42117 42102 42103>, <41871 41821 41860 41873 41858 41860>, <41633 41600 41619 41631 41619 41621>, <41399 41388 41383 41394 41383 41386>, <41159 41177 41151 41164 41153 41156>, <40914 40966 40926 40940 40928 40931>, <40664 40748 40713 40723 40712 40714>, <40399 40518 40523 40513 40504 40504>, <40124 40275 40331 40309 40304 40303>, <39875 40020 40107 40121 40118 40117>, <39661 39745 39855 39943 39940 39943>, <39463 39490 39610 39740 39745 39753>, <39272 39274 39366 39484 39512 39529>, <39092 39081 39141 39230 39277 39300>, <38921 38899 38954 39025 39068 39092>, <38761 38732 38792 38844 38874 38893>, <38608 38570 38644 38692 38717 38732>, <38455 38400 38508 38565 38591 38604>, <38298 38240 38384 38453 38482 38493>, <38177 38131 38274 38351 38379 38388>, <38097 38053 38173 38257 38284 38291>, <38035 37991 38077 38170 38199 38204>, <37974 37941 37981 38089 38124 38127>, <37917 37899 37902 38013 38052 38054>, <37860 37854 37852 37943 37983 37983>, <37804 37810 37814 37877 37916 37913>, <37748 37763 37773 37808 37837 37827>, <37688 37713 37732 37737 37742 37714>, <37625 37659 37685 37663 37644 37600>, <37555 37594 37625 37586 37553 37504>, <37478 37517 37552 37506 37462 37415>, <37392 37429 37462 37421 37371 37324>, <37304 37325 37343 37328 37281 37234>, <37214 37203 37202 37207 37163 37117>, <37126 37060 37035 37060 37016 36963>, <37043 36917 36876 36927 36898 36847>, <36964 36795 36775 36869 36852 36802>, <36921 36753 36741 36856 36843 36792>, <36874 36721 36707 36836 36830 36778>, <36825 36686 36658 36806 36806 36754>, <36775 36650 36561 36730 36741 36684>, <36718 36587 36342 36481 36468 36393>, <36628 36375 35879 35970 35978 35909>, <36444 35829 35213 35307 35336 35270>, <36058 34987 34182 34372 34446 34386>, <35309 33627 32498 32933 33098 33056>, <34358 32180 27628 27596 28297 29138>;
			};

			qcom,pc-temp-z1-lut {
				qcom,lut-col-legend = <0 10 25 40 50>;
				qcom,lut-row-legend = <10000 9800 9600 9400 9200>, <9000 8800 8600 8400 8200>, <8000 7800 7600 7400 7200>, <7000 6800 6600 6400 6200>, <6000 5800 5600 5400 5200>, <5000 4800 4600 4400 4200>, <4000 3800 3600 3400 3200>, <3000 2800 2600 2400 2200>, <2000 1800 1600 1400 1200>, <1000 900 800 700 600>, <500 400 300 200 100>, <0>;
				qcom,lut-data = <12204 11706 11262 11001 10896>, <12196 11686 11277 10982 10877>, <12184 11668 11252 10970 10870>, <12172 11653 11231 10960 10866>, <12159 11640 11222 10953 10861>, <12148 11629 11215 10946 10856>, <12140 11619 11205 10941 10852>, <12126 11609 11188 10935 10849>, <12109 11597 11176 10931 10847>, <12092 11585 11172 10929 10845>, <12070 11573 11170 10928 10844>, <12054 11559 11169 10927 10843>, <12045 11550 11169 10925 10843>, <12039 11555 11168 10924 10842>, <12033 11564 11167 10924 10843>, <12020 11567 11165 10924 10843>, <12009 11565 11165 10925 10843>, <12010 11564 11165 10925 10845>, <12013 11563 11165 10926 10846>, <12017 11562 11167 10928 10847>, <12045 11562 11170 10930 10848>, <12076 11567 11172 10930 10849>, <12073 11572 11174 10930 10851>, <12047 11574 11176 10930 10854>, <12028 11576 11177 10932 10855>, <12032 11579 11178 10937 10857>, <12041 11582 11182 10941 10859>, <12046 11587 11188 10945 10862>, <12078 11591 11192 10948 10865>, <12107 11597 11193 10951 10867>, <12096 11602 11195 10954 10870>, <12063 11606 11198 10957 10873>, <12055 11609 11204 10960 10876>, <12170 11613 11209 10963 10879>, <12308 11617 11212 10967 10883>, <12301 11621 11215 10971 10886>, <12175 11629 11220 10976 10890>, <12097 11638 11225 10979 10893>, <12107 11647 11231 10983 10896>, <12123 11657 11238 10988 10899>, <12136 11665 11245 10992 10902>, <12148 11672 11250 10995 10906>, <12160 11678 11255 10999 10909>, <12171 11687 11263 11002 10911>, <12194 11687 11270 11006 10914>, <12293 11695 11272 11010 10915>, <12420 11687 11276 11010 10915>, <12184 11694 11279 11009 10915>, <12192 11691 11271 11011 10917>, <12217 11704 11278 11017 10920>, <12236 11722 11294 11022 10925>, <12231 11727 11294 11030 10932>, <12236 11731 11311 11039 10940>, <12246 11787 11323 11053 10953>, <12246 11787 11323 11053 10953>, <12246 11787 11323 11053 10953>;
			};

			qcom,pc-temp-z2-lut {
				qcom,lut-col-legend = <0 10 25 40 50>;
				qcom,lut-row-legend = <10000 9800 9600 9400 9200>, <9000 8800 8600 8400 8200>, <8000 7800 7600 7400 7200>, <7000 6800 6600 6400 6200>, <6000 5800 5600 5400 5200>, <5000 4800 4600 4400 4200>, <4000 3800 3600 3400 3200>, <3000 2800 2600 2400 2200>, <2000 1800 1600 1400 1200>, <1000 900 800 700 600>, <500 400 300 200 100>, <0>;
				qcom,lut-data = <10284 10847 10786 10263 10161>, <10233 10635 10454 10337 10153>, <10288 10501 10514 10333 10154>, <10328 10461 10553 10331 10163>, <10318 10426 10526 10319 10161>, <10296 10391 10466 10284 10142>, <10287 10352 10417 10256 10128>, <10286 10326 10373 10206 10105>, <10285 10313 10349 10161 10078>, <10280 10302 10350 10158 10076>, <10267 10301 10352 10148 10080>, <10255 10315 10354 10140 10086>, <10246 10336 10356 10138 10097>, <10239 10355 10360 10136 10108>, <10239 10377 10374 10141 10118>, <10247 10398 10395 10156 10137>, <10258 10419 10409 10168 10146>, <10270 10439 10420 10179 10151>, <10285 10458 10431 10192 10156>, <10301 10476 10441 10205 10163>, <10318 10492 10453 10223 10178>, <10335 10513 10508 10281 10198>, <10354 10531 10649 10490 10239>, <10373 10546 10713 10627 10271>, <10391 10567 10602 10509 10280>, <10404 10573 10474 10323 10285>, <10416 10556 10464 10310 10283>, <10426 10538 10471 10407 10259>, <10437 10537 10483 10462 10225>, <10445 10538 10535 10400 10157>, <10448 10541 10583 10301 10086>, <10451 10549 10568 10241 10078>, <10454 10561 10520 10192 10090>, <10461 10569 10503 10176 10106>, <10470 10577 10517 10198 10129>, <10475 10584 10539 10235 10161>, <10478 10592 10558 10270 10210>, <10483 10601 10581 10310 10282>, <10494 10616 10613 10347 10334>, <10511 10637 10671 10387 10368>, <10528 10652 10713 10416 10388>, <10547 10658 10702 10426 10389>, <10571 10664 10681 10433 10385>, <10607 10676 10675 10449 10395>, <10882 10796 10701 10455 10400>, <10947 10853 10728 10472 10353>, <10888 10864 10706 10448 10341>, <10742 10939 10676 10450 10369>, <10689 11060 10669 10465 10388>, <10611 11173 10731 10534 10481>, <10241 11165 10724 10488 10377>, <10324 11112 10669 10361 10214>, <10381 10920 10650 10285 10149>, <10169 10591 10585 10235 10098>, <10169 10591 10585 10235 10098>, <10169 10591 10585 10235 10098>;
			};

			qcom,pc-temp-z3-lut {
				qcom,lut-col-legend = <0 10 25 40 50>;
				qcom,lut-row-legend = <10000 9800 9600 9400 9200>, <9000 8800 8600 8400 8200>, <8000 7800 7600 7400 7200>, <7000 6800 6600 6400 6200>, <6000 5800 5600 5400 5200>, <5000 4800 4600 4400 4200>, <4000 3800 3600 3400 3200>, <3000 2800 2600 2400 2200>, <2000 1800 1600 1400 1200>, <1000 900 800 700 600>, <500 400 300 200 100>, <0>;
				qcom,lut-data = <19500 19556 19409 19344 19330>, <19619 19541 19402 19377 19365>, <19696 19536 19428 19386 19375>, <19740 19550 19442 19391 19379>, <19755 19566 19444 19395 19384>, <19765 19569 19446 19398 19391>, <19766 19569 19447 19399 19393>, <19759 19568 19448 19401 19392>, <19749 19565 19449 19403 19390>, <19742 19559 19445 19402 19389>, <19736 19552 19438 19396 19388>, <19730 19543 19432 19392 19387>, <19723 19533 19427 19390 19386>, <19717 19526 19423 19389 19383>, <19711 19519 19419 19387 19381>, <19703 19514 19416 19385 19377>, <19693 19511 19414 19383 19374>, <19679 19507 19411 19381 19371>, <19662 19501 19409 19378 19368>, <19651 19494 19404 19372 19364>, <19645 19492 19400 19365 19358>, <19641 19495 19405 19365 19358>, <19641 19500 19424 19378 19363>, <19643 19505 19433 19387 19368>, <19646 19512 19416 19377 19368>, <19653 19514 19396 19360 19367>, <19662 19504 19395 19364 19370>, <19664 19495 19398 19396 19391>, <19660 19494 19403 19415 19404>, <19654 19495 19420 19411 19399>, <19649 19497 19436 19405 19391>, <19642 19501 19435 19397 19384>, <19637 19506 19428 19389 19379>, <19633 19506 19423 19381 19372>, <19629 19505 19418 19375 19363>, <19625 19504 19414 19370 19354>, <19621 19500 19409 19365 19349>, <19617 19495 19404 19359 19345>, <19612 19490 19401 19358 19344>, <19607 19486 19400 19359 19344>, <19601 19481 19399 19360 19344>, <19592 19478 19396 19359 19347>, <19583 19473 19392 19358 19352>, <19573 19466 19388 19359 19356>, <19498 19440 19380 19359 19356>, <19477 19422 19372 19347 19344>, <19432 19419 19368 19343 19343>, <19308 19391 19364 19340 19331>, <19303 19333 19353 19333 19327>, <19295 19333 19347 19330 19322>, <19273 19331 19352 19342 19333>, <19288 19326 19356 19357 19347>, <19305 19321 19351 19358 19349>, <19326 19346 19350 19353 19350>, <19326 19346 19350 19353 19350>, <19326 19346 19350 19353 19350>;
			};

			qcom,pc-temp-z4-lut {
				qcom,lut-col-legend = <0 10 25 40 50>;
				qcom,lut-row-legend = <10000 9800 9600 9400 9200>, <9000 8800 8600 8400 8200>, <8000 7800 7600 7400 7200>, <7000 6800 6600 6400 6200>, <6000 5800 5600 5400 5200>, <5000 4800 4600 4400 4200>, <4000 3800 3600 3400 3200>, <3000 2800 2600 2400 2200>, <2000 1800 1600 1400 1200>, <1000 900 800 700 600>, <500 400 300 200 100>, <0>;
				qcom,lut-data = <15851 15200 14875 14892 14780>, <16118 15302 15114 14909 14860>, <15930 15325 15038 14882 14845>, <15709 15240 14952 14836 14811>, <15541 15106 14899 14806 14787>, <15385 15013 14854 14782 14767>, <15264 14948 14818 14762 14750>, <15170 14897 14787 14740 14732>, <15092 14857 14763 14723 14718>, <15026 14825 14746 14715 14711>, <14970 14799 14732 14710 14707>, <14923 14775 14724 14706 14704>, <14883 14758 14720 14701 14701>, <14850 14750 14716 14697 14697>, <14821 14745 14711 14692 14694>, <14792 14741 14706 14687 14691>, <14777 14738 14702 14683 14688>, <14778 14736 14699 14679 14685>, <14784 14730 14695 14676 14682>, <14785 14722 14691 14672 14676>, <14770 14719 14688 14669 14670>, <14753 14721 14701 14676 14676>, <14751 14726 14756 14734 14737>, <14752 14758 14796 14780 14784>, <14753 14830 14817 14787 14779>, <14786 14858 14829 14791 14766>, <14835 14847 14824 14782 14747>, <14847 14830 14801 14733 14714>, <14847 14815 14777 14700 14692>, <14846 14799 14750 14695 14688>, <14841 14784 14728 14691 14685>, <14827 14769 14720 14689 14681>, <14814 14757 14716 14686 14677>, <14803 14750 14714 14684 14674>, <14792 14745 14713 14682 14671>, <14780 14741 14712 14681 14670>, <14768 14736 14711 14681 14670>, <14757 14732 14709 14682 14670>, <14745 14729 14709 14684 14671>, <14734 14727 14711 14691 14683>, <14728 14725 14714 14698 14694>, <14724 14716 14709 14695 14690>, <14717 14705 14699 14689 14681>, <14700 14698 14694 14687 14686>, <14695 14679 14679 14679 14681>, <14696 14668 14660 14661 14657>, <14743 14664 14656 14658 14651>, <14878 14683 14649 14649 14647>, <14880 14741 14646 14637 14633>, <14884 14733 14643 14628 14624>, <14901 14737 14651 14647 14654>, <14883 14758 14661 14651 14661>, <14888 14770 14668 14654 14667>, <14891 14757 14672 14661 14667>, <14891 14757 14672 14661 14667>, <14891 14757 14672 14661 14667>;
			};

			qcom,pc-temp-z5-lut {
				qcom,lut-col-legend = <0 10 25 40 50>;
				qcom,lut-row-legend = <10000 9800 9600 9400 9200>, <9000 8800 8600 8400 8200>, <8000 7800 7600 7400 7200>, <7000 6800 6600 6400 6200>, <6000 5800 5600 5400 5200>, <5000 4800 4600 4400 4200>, <4000 3800 3600 3400 3200>, <3000 2800 2600 2400 2200>, <2000 1800 1600 1400 1200>, <1000 900 800 700 600>, <500 400 300 200 100>, <0>;
				qcom,lut-data = <12685 15042 15643 14394 14663>, <13358 15325 15502 17243 17588>, <14059 15683 16925 18187 19154>, <14693 16190 17909 19103 20068>, <15190 16877 18378 19737 21230>, <15623 17514 18706 20171 22540>, <16058 18072 19249 20691 23700>, <16510 18666 20157 22038 24628>, <17018 19361 21051 23495 25465>, <17643 20136 21834 23772 26310>, <18392 20998 22498 23631 27152>, <19234 22044 22704 23798 27987>, <20212 22927 22680 24603 28953>, <21402 23450 22723 25569 29848>, <23006 23881 23114 26421 30512>, <25565 24432 23769 27447 31109>, <27204 25466 24473 28506 31437>, <26656 26251 25316 29937 32731>, <25308 26274 26102 30818 33901>, <24811 26121 26610 30155 34233>, <25743 26442 27217 28898 34826>, <27533 31175 31183 29414 34985>, <30390 36565 42650 34734 34887>, <35648 38665 47789 38404 34684>, <41327 40215 36446 31156 29594>, <48076 40331 22897 19637 20920>, <54210 34389 20818 18784 20289>, <54958 28097 20273 24922 26973>, <51047 27428 20353 29385 31623>, <46370 27325 25290 30798 32192>, <42919 27372 31003 31630 32427>, <39778 29614 32461 31440 32559>, <38104 33034 33139 30424 32938>, <37276 35758 34031 29959 32872>, <36785 38410 35602 30594 31011>, <36672 39544 36718 31282 29007>, <36668 39589 36504 31065 28816>, <36744 39474 35872 30329 28825>, <37967 39181 35536 30067 28790>, <39825 38423 35409 30271 28204>, <40126 37589 35162 30462 27626>, <39002 36757 33584 29288 28071>, <38811 35947 31288 27276 29611>, <40671 34999 30283 28775 33341>, <31818 33172 30870 30364 35120>, <27444 30153 31516 26388 28439>, <23002 28844 28947 24320 26339>, <12393 20001 28519 24354 22026>, <12260 14154 24027 24960 24852>, <12076 14370 23220 27397 28871>, <11731 14217 23760 28236 26766>, <12042 13575 21103 26537 23305>, <12160 13167 18667 23862 20440>, <12675 14088 17777 19307 17859>, <12675 14088 17777 19307 17859>, <12675 14088 17777 19307 17859>;
			};

			qcom,pc-temp-z6-lut {
				qcom,lut-col-legend = <0 10 25 40 50>;
				qcom,lut-row-legend = <10000 9800 9600 9400 9200>, <9000 8800 8600 8400 8200>, <8000 7800 7600 7400 7200>, <7000 6800 6600 6400 6200>, <6000 5800 5600 5400 5200>, <5000 4800 4600 4400 4200>, <4000 3800 3600 3400 3200>, <3000 2800 2600 2400 2200>, <2000 1800 1600 1400 1200>, <1000 900 800 700 600>, <500 400 300 200 100>, <0>;
				qcom,lut-data = <15629 15078 14680 14586 14511>, <15760 15087 14770 14604 14560>, <15687 15085 14745 14594 14555>, <15594 15049 14714 14578 14543>, <15510 14981 14690 14566 14535>, <15423 14932 14668 14556 14530>, <15350 14893 14649 14547 14524>, <15288 14861 14634 14539 14516>, <15235 14834 14621 14532 14509>, <15190 14812 14609 14526 14505>, <15151 14791 14599 14521 14503>, <15118 14772 14591 14516 14500>, <15090 14758 14586 14513 14497>, <15065 14749 14582 14510 14495>, <15043 14743 14577 14506 14492>, <15021 14738 14573 14503 14488>, <15005 14734 14570 14500 14485>, <14997 14730 14567 14497 14482>, <14992 14724 14564 14494 14479>, <14986 14718 14560 14489 14475>, <14979 14716 14557 14484 14469>, <14973 14719 14567 14487 14471>, <14973 14725 14603 14521 14500>, <14977 14744 14620 14544 14522>, <14984 14779 14620 14542 14520>, <15005 14791 14618 14537 14515>, <15031 14784 14615 14534 14512>, <15037 14774 14608 14532 14510>, <15037 14768 14603 14529 14507>, <15037 14763 14602 14525 14503>, <15033 14759 14600 14521 14498>, <15025 14757 14597 14517 14494>, <15019 14755 14593 14511 14489>, <15016 14754 14590 14507 14484>, <15012 14752 14588 14503 14479>, <15009 14751 14586 14500 14473>, <15005 14749 14584 14498 14470>, <15003 14748 14582 14495 14468>, <15004 14749 14582 14495 14468>, <15005 14749 14584 14499 14473>, <15007 14750 14586 14503 14478>, <15012 14749 14584 14502 14478>, <15014 14747 14579 14499 14478>, <15016 14746 14577 14500 14482>, <14996 14733 14570 14497 14480>, <14990 14723 14560 14484 14464>, <14988 14720 14556 14481 14461>, <14984 14716 14552 14475 14454>, <14983 14712 14545 14466 14445>, <14985 14713 14543 14461 14438>, <14988 14719 14552 14476 14457>, <14997 14731 14562 14489 14472>, <15018 14741 14566 14494 14477>, <15047 14763 14574 14498 14481>, <15047 14763 14574 14498 14481>, <15047 14763 14574 14498 14481>;
			};

			qcom,pc-temp-y1-lut {
				qcom,lut-col-legend = <(-10) 0 10 25 40 50>;
				qcom,lut-row-legend = <10000 9800 9600 9400 9200 9000>, <8800 8600 8400 8200 8000 7800>, <7600 7400 7200 7000 6800 6600>, <6400 6200 6000 5800 5600 5400>, <5200 5000 4800 4600 4400 4200>, <4000 3800 3600 3400 3200 3000>, <2800 2600 2400 2200 2000 1800>, <1600 1400 1200 1000 900 800>, <700 600 500 400 300 200>, <100 0>;
				qcom,lut-data = <5783 5465 5262 4997 4827 4770>, <5801 5473 5251 4992 4828 4769>, <5814 5478 5240 4988 4828 4769>, <5823 5482 5230 4983 4827 4769>, <5828 5484 5222 4980 4827 4768>, <5830 5486 5219 4977 4826 4768>, <5825 5496 5220 4975 4825 4767>, <5815 5511 5222 4974 4823 4767>, <5811 5511 5221 4973 4821 4766>, <5809 5490 5215 4973 4820 4765>, <5807 5475 5211 4972 4819 4765>, <5806 5473 5213 4969 4818 4764>, <5804 5472 5214 4965 4818 4764>, <5804 5471 5214 4964 4817 4764>, <5806 5471 5214 4963 4817 4764>, <5808 5471 5214 4963 4817 4765>, <5812 5475 5215 4962 4816 4764>, <5817 5480 5216 4961 4816 4764>, <5820 5481 5217 4962 4816 4764>, <5819 5481 5219 4964 4816 4765>, <5817 5481 5220 4965 4817 4766>, <5817 5482 5222 4967 4818 4767>, <5816 5486 5224 4969 4820 4768>, <5815 5490 5225 4972 4821 4770>, <5811 5500 5225 4975 4824 4773>, <5807 5506 5225 4977 4826 4774>, <5810 5499 5224 4978 4828 4775>, <5824 5489 5224 4979 4829 4775>, <5831 5485 5226 4981 4831 4776>, <5821 5483 5230 4985 4832 4779>, <5806 5483 5232 4988 4834 4781>, <5803 5491 5231 4993 4837 4782>, <5808 5506 5230 4996 4840 4784>, <5812 5509 5233 4996 4842 4786>, <5809 5498 5236 4995 4845 4789>, <5802 5489 5238 4996 4847 4791>, <5801 5490 5240 5002 4849 4792>, <5804 5492 5241 5005 4850 4793>, <5806 5493 5240 5004 4851 4794>, <5803 5493 5239 5003 4851 4795>, <5796 5495 5240 5004 4852 4796>, <5796 5495 5245 5008 4853 4797>, <5820 5494 5246 5012 4854 4798>, <5829 5496 5247 5017 4855 4801>, <5802 5500 5253 5024 4861 4804>, <5829 5519 5265 5031 4864 4806>, <5844 5527 5265 5031 4864 4807>, <5862 5538 5273 5031 4865 4807>, <5873 5542 5275 5030 4868 4807>, <5914 5541 5266 5035 4865 4808>, <5896 5546 5289 5035 4866 4810>, <5978 5581 5308 5045 4873 4813>, <6015 5646 5364 5061 4879 4820>, <6091 5674 5407 5081 4888 4828>, <6091 5674 5407 5081 4888 4828>, <6091 5674 5407 5081 4888 4828>;
			};

			qcom,pc-temp-y2-lut {
				qcom,lut-col-legend = <(-10) 0 10 25 40 50>;
				qcom,lut-row-legend = <10000 9800 9600 9400 9200 9000>, <8800 8600 8400 8200 8000 7800>, <7600 7400 7200 7000 6800 6600>, <6400 6200 6000 5800 5600 5400>, <5200 5000 4800 4600 4400 4200>, <4000 3800 3600 3400 3200 3000>, <2800 2600 2400 2200 2000 1800>, <1600 1400 1200 1000 900 800>, <700 600 500 400 300 200>, <100 0>;
				qcom,lut-data = <10571 10657 11150 11437 11089 11058>, <10601 10690 11159 11362 11043 11010>, <10650 10743 11156 11287 10992 10955>, <10704 10801 11145 11216 10943 10900>, <10750 10848 11128 11155 10902 10855>, <10775 10867 11107 11111 10875 10827>, <10779 10863 11076 11080 10862 10814>, <10781 10858 11041 11055 10852 10804>, <10788 10860 11016 11032 10840 10788>, <10815 10882 10994 11009 10825 10756>, <10848 10907 10986 10990 10807 10738>, <10870 10924 10995 10973 10780 10746>, <10890 10943 11016 10961 10756 10757>, <10923 10983 11051 10964 10756 10748>, <11007 11089 11112 10983 10769 10722>, <11077 11166 11174 11010 10776 10708>, <11080 11204 11232 11061 10769 10706>, <11075 11241 11286 11133 10763 10707>, <11074 11244 11336 11232 10799 10724>, <11083 11218 11383 11356 10919 10780>, <11094 11199 11398 11397 11012 10840>, <11100 11214 11387 11380 11071 10909>, <11104 11239 11376 11355 11108 10967>, <11106 11242 11381 11328 11101 10992>, <11092 11226 11397 11293 11070 11012>, <11066 11200 11407 11285 11062 11019>, <11041 11159 11416 11329 11095 11022>, <11014 11097 11422 11378 11131 11029>, <10965 10972 11415 11410 11156 11049>, <10526 10632 11396 11448 11194 11090>, <9898 10425 11388 11477 11213 11135>, <9742 10297 11388 11516 11251 11191>, <9722 10054 11387 11540 11299 11235>, <9710 9925 11373 11529 11340 11251>, <9701 9801 11341 11504 11377 11263>, <9693 9719 11300 11485 11383 11261>, <9687 9697 11235 11468 11344 11222>, <9682 9684 11155 11452 11292 11186>, <9678 9676 11067 11432 11235 11177>, <9674 9672 10962 11408 11176 11166>, <9672 9668 10847 11395 11170 11145>, <9670 9665 10716 11378 11204 11081>, <9668 9663 10429 11344 11207 11061>, <9667 9662 9941 11267 11166 11068>, <9665 9660 9774 11205 11114 11014>, <9663 9659 9726 11157 11070 10885>, <9662 9658 9695 11179 10986 10851>, <9661 9658 9678 11171 10993 10860>, <9659 9657 9669 11156 11010 10835>, <9656 9656 9663 11155 11063 10850>, <9652 9654 9658 11076 11002 10837>, <9649 9650 9655 10971 10916 10779>, <9648 9648 9652 10827 10806 10677>, <9647 9648 9651 10641 10671 10545>, <9647 9648 9651 10641 10671 10545>, <9647 9648 9651 10641 10671 10545>;
			};

			qcom,pc-temp-y3-lut {
				qcom,lut-col-legend = <(-10) 0 10 25 40 50>;
				qcom,lut-row-legend = <10000 9800 9600 9400 9200 9000>, <8800 8600 8400 8200 8000 7800>, <7600 7400 7200 7000 6800 6600>, <6400 6200 6000 5800 5600 5400>, <5200 5000 4800 4600 4400 4200>, <4000 3800 3600 3400 3200 3000>, <2800 2600 2400 2200 2000 1800>, <1600 1400 1200 1000 900 800>, <700 600 500 400 300 200>, <100 0>;
				qcom,lut-data = <13427 13399 13328 13294 13281 13277>, <13431 13402 13331 13294 13281 13278>, <13437 13407 13334 13294 13281 13279>, <13445 13412 13337 13294 13282 13280>, <13452 13416 13340 13295 13283 13281>, <13455 13418 13342 13295 13283 13282>, <13456 13420 13344 13295 13284 13282>, <13456 13420 13346 13296 13285 13283>, <13456 13420 13347 13297 13286 13283>, <13454 13417 13349 13297 13286 13284>, <13452 13415 13350 13298 13286 13284>, <13458 13422 13351 13298 13286 13285>, <13473 13433 13351 13298 13287 13285>, <13476 13429 13350 13299 13287 13286>, <13443 13398 13345 13302 13287 13286>, <13410 13377 13341 13304 13288 13286>, <13411 13384 13338 13304 13290 13286>, <13419 13395 13336 13305 13292 13286>, <13422 13395 13334 13304 13293 13288>, <13413 13380 13333 13303 13294 13291>, <13401 13366 13330 13302 13294 13292>, <13395 13361 13325 13300 13292 13290>, <13392 13357 13320 13297 13288 13286>, <13389 13352 13317 13293 13285 13283>, <13386 13346 13316 13290 13281 13280>, <13383 13341 13314 13288 13280 13279>, <13375 13338 13312 13288 13280 13279>, <13354 13334 13311 13288 13280 13279>, <13342 13327 13309 13288 13279 13279>, <13347 13306 13308 13289 13279 13278>, <13358 13293 13307 13289 13278 13278>, <13367 13303 13306 13288 13279 13278>, <13377 13323 13305 13288 13279 13278>, <13389 13339 13306 13287 13279 13278>, <13404 13354 13308 13287 13280 13280>, <13421 13372 13310 13287 13280 13280>, <13442 13391 13312 13287 13280 13279>, <13466 13413 13315 13287 13279 13278>, <13494 13444 13318 13287 13279 13278>, <13524 13490 13321 13287 13280 13278>, <13559 13546 13325 13288 13280 13279>, <13597 13612 13329 13290 13282 13280>, <13636 13689 13336 13291 13281 13280>, <13687 13774 13345 13290 13279 13277>, <13755 13881 13366 13290 13278 13276>, <13871 13933 13386 13292 13283 13281>, <13912 14009 13415 13296 13286 13284>, <13972 14105 13451 13300 13289 13286>, <14134 14205 13540 13304 13290 13288>, <14448 14367 13678 13307 13290 13286>, <15515 14771 13926 13306 13286 13284>, <19236 16874 14326 13307 13285 13283>, <29316 26004 15413 13318 13289 13286>, <65535 65535 23721 13338 13296 13295>, <65535 65535 23721 13338 13296 13295>, <65535 65535 23721 13338 13296 13295>;
			};

			qcom,pc-temp-y4-lut {
				qcom,lut-col-legend = <(-10) 0 10 25 40 50>;
				qcom,lut-row-legend = <10000 9800 9600 9400 9200 9000>, <8800 8600 8400 8200 8000 7800>, <7600 7400 7200 7000 6800 6600>, <6400 6200 6000 5800 5600 5400>, <5200 5000 4800 4600 4400 4200>, <4000 3800 3600 3400 3200 3000>, <2800 2600 2400 2200 2000 1800>, <1600 1400 1200 1000 900 800>, <700 600 500 400 300 200>, <100 0>;
				qcom,lut-data = <16684 16693 16578 16495 16457 16456>, <16729 16740 16615 16496 16459 16458>, <16791 16811 16653 16498 16460 16460>, <16857 16886 16687 16498 16461 16461>, <16913 16946 16710 16499 16462 16462>, <16944 16971 16719 16499 16462 16462>, <16955 16965 16713 16499 16461 16461>, <16961 16955 16702 16498 16460 16460>, <16962 16952 16693 16498 16460 16460>, <16961 16951 16686 16500 16462 16460>, <16959 16951 16683 16502 16464 16460>, <16943 16952 16685 16507 16467 16460>, <16911 16956 16691 16514 16470 16462>, <16904 16977 16703 16519 16473 16463>, <16959 17063 16729 16524 16478 16466>, <17013 17119 16759 16531 16483 16470>, <16976 17078 16800 16547 16488 16475>, <16861 16992 16834 16568 16496 16481>, <16797 16921 16821 16599 16512 16492>, <16782 16853 16768 16640 16539 16509>, <16771 16800 16715 16650 16549 16516>, <16755 16767 16663 16603 16540 16516>, <16736 16742 16619 16545 16526 16515>, <16715 16716 16597 16514 16503 16503>, <16686 16691 16581 16491 16472 16472>, <16660 16661 16570 16485 16462 16459>, <16650 16608 16561 16484 16462 16458>, <16644 16552 16554 16484 16462 16457>, <16642 16549 16548 16487 16464 16458>, <16657 16589 16542 16492 16470 16462>, <16684 16618 16533 16497 16476 16468>, <16700 16617 16511 16501 16485 16475>, <16710 16615 16496 16504 16492 16484>, <16717 16625 16500 16506 16499 16493>, <16724 16644 16512 16506 16505 16502>, <16729 16664 16527 16505 16505 16503>, <16734 16684 16547 16493 16493 16488>, <16738 16701 16569 16483 16482 16476>, <16740 16705 16589 16481 16476 16476>, <16736 16705 16608 16480 16472 16479>, <16727 16704 16619 16483 16473 16483>, <16722 16700 16624 16494 16480 16493>, <16721 16690 16626 16497 16478 16491>, <16724 16677 16627 16497 16460 16463>, <16743 16663 16624 16490 16445 16442>, <16759 16646 16618 16491 16455 16461>, <16757 16649 16636 16506 16480 16493>, <16750 16660 16680 16526 16514 16530>, <16763 16677 16702 16563 16551 16565>, <16778 16700 16751 16593 16570 16581>, <16854 16728 16801 16584 16500 16493>, <17305 16912 16816 16551 16474 16476>, <18698 18300 16947 16584 16477 16475>, <24018 32152 21389 16634 16486 16474>, <24018 32152 21389 16634 16486 16474>, <24018 32152 21389 16634 16486 16474>;
			};

			qcom,pc-temp-y5-lut {
				qcom,lut-col-legend = <(-10) 0 10 25 40 50>;
				qcom,lut-row-legend = <10000 9800 9600 9400 9200 9000>, <8800 8600 8400 8200 8000 7800>, <7600 7400 7200 7000 6800 6600>, <6400 6200 6000 5800 5600 5400>, <5200 5000 4800 4600 4400 4200>, <4000 3800 3600 3400 3200 3000>, <2800 2600 2400 2200 2000 1800>, <1600 1400 1200 1000 900 800>, <700 600 500 400 300 200>, <100 0>;
				qcom,lut-data = <14678 14829 17490 23102 20927 18854>, <15189 15284 17611 21960 20389 19488>, <15683 15746 17728 20708 19891 20101>, <16143 16181 17840 19503 19471 20623>, <16551 16556 17947 18501 19167 20982>, <16890 16836 18050 17860 19013 21109>, <17154 17060 18169 17536 19066 21017>, <17377 17224 18265 17290 19149 20820>, <17585 17186 18229 16942 18886 20543>, <17742 16847 17983 16480 18042 20072>, <17970 16625 17671 16066 17331 19637>, <19184 17336 17316 15494 16899 19256>, <21400 18472 16866 14998 16492 18842>, <21984 18488 16181 15028 16039 18320>, <19677 17294 15202 15287 15541 17514>, <17406 16492 14832 15388 15356 16805>, <18613 19099 15950 15023 15494 16129>, <22330 23284 17772 14632 15667 15638>, <23864 23869 19535 14872 15621 15653>, <22625 22296 21467 15898 15374 15907>, <21223 21221 22327 17384 15503 16369>, <21194 21684 22528 20688 18708 18725>, <21682 22534 22622 23352 21945 21122>, <22182 22956 22808 22711 21672 21362>, <22681 23193 23274 20891 20329 21286>, <23079 23352 23459 20271 19561 21107>, <22043 22964 23245 20269 19198 20663>, <17245 21848 23071 20301 18866 20031>, <13949 20123 23575 20586 18266 19145>, <13397 15827 24616 21138 17297 18007>, <13090 13253 24862 21410 17006 17514>, <13050 13550 23886 21595 17204 17362>, <13094 14076 22741 21860 17556 17292>, <13169 14212 22136 22539 18390 18067>, <13361 14256 21650 23492 19826 19933>, <13674 14321 21054 23935 21025 20901>, <13928 14458 20213 24159 22111 21255>, <14181 14656 19632 24123 22886 21547>, <14327 14887 19392 23075 23297 22020>, <14313 15224 19156 21625 23571 22566>, <14258 15419 19000 21344 23582 22799>, <14135 15318 18901 21453 23338 22885>, <13631 15078 18380 20952 23093 23073>, <13249 14669 16823 19714 22532 23728>, <12840 14480 15571 18911 19341 19901>, <12970 13990 14836 19310 19758 18798>, <12983 14029 14701 19748 18779 16966>, <13045 14142 14068 19061 17619 15705>, <13163 14003 14590 18634 16642 15233>, <13352 14092 14463 18325 16318 14811>, <12992 14253 14348 18220 16462 16344>, <11118 12338 13839 18979 17351 15927>, <9813 9876 12878 18569 18159 16082>, <9282 9134 9536 18321 20902 20007>, <9282 9134 9536 18321 20902 20007>, <9282 9134 9536 18321 20902 20007>;
			};

			qcom,pc-temp-y6-lut {
				qcom,lut-col-legend = <(-10) 0 10 25 40 50>;
				qcom,lut-row-legend = <10000 9800 9600 9400 9200 9000>, <8800 8600 8400 8200 8000 7800>, <7600 7400 7200 7000 6800 6600>, <6400 6200 6000 5800 5600 5400>, <5200 5000 4800 4600 4400 4200>, <4000 3800 3600 3400 3200 3000>, <2800 2600 2400 2200 2000 1800>, <1600 1400 1200 1000 900 800>, <700 600 500 400 300 200>, <100 0>;
				qcom,lut-data = <5597 5391 5166 5027 4981 4972>, <5606 5411 5180 5026 4982 4973>, <5612 5427 5190 5026 4983 4975>, <5616 5439 5196 5026 4983 4976>, <5619 5447 5199 5025 4984 4977>, <5620 5450 5199 5025 4984 4977>, <5619 5446 5197 5025 4985 4978>, <5616 5440 5191 5025 4985 4978>, <5612 5434 5187 5025 4986 4978>, <5607 5428 5183 5025 4986 4978>, <5603 5425 5182 5026 4987 4979>, <5601 5428 5182 5027 4988 4979>, <5599 5432 5182 5028 4989 4980>, <5598 5436 5182 5031 4990 4981>, <5594 5440 5185 5034 4992 4982>, <5588 5442 5189 5038 4993 4983>, <5577 5436 5198 5042 4996 4985>, <5558 5422 5207 5048 5000 4987>, <5545 5404 5203 5056 5005 4991>, <5538 5376 5186 5067 5014 4998>, <5532 5354 5169 5069 5016 5001>, <5528 5345 5151 5054 5012 4999>, <5525 5339 5136 5036 5005 4996>, <5523 5333 5129 5024 4996 4989>, <5522 5328 5125 5016 4985 4978>, <5521 5322 5122 5013 4981 4974>, <5519 5313 5120 5013 4981 4974>, <5516 5305 5119 5014 4981 4974>, <5515 5304 5118 5015 4982 4974>, <5524 5315 5118 5017 4983 4975>, <5542 5330 5117 5019 4985 4976>, <5561 5350 5114 5021 4987 4979>, <5582 5377 5112 5022 4990 4981>, <5605 5407 5115 5023 4993 4985>, <5630 5442 5125 5024 4995 4988>, <5658 5481 5137 5024 4995 4988>, <5689 5525 5151 5021 4992 4984>, <5721 5575 5169 5019 4988 4980>, <5755 5627 5190 5019 4987 4980>, <5789 5684 5214 5020 4986 4981>, <5822 5745 5242 5021 4987 4983>, <5860 5809 5272 5028 4990 4987>, <5901 5879 5306 5031 4990 4986>, <5952 5955 5345 5032 4983 4976>, <6020 6048 5393 5033 4978 4970>, <6128 6098 5431 5036 4986 4980>, <6172 6163 5491 5045 4995 4991>, <6235 6248 5569 5055 5007 5003>, <6387 6344 5682 5069 5018 5015>, <6677 6494 5840 5080 5024 5019>, <7628 6853 6088 5079 5001 4992>, <10633 8573 6444 5074 4994 4987>, <18112 15475 7378 5105 4999 4990>, <45554 57048 14280 5156 5008 4997>, <45554 57048 14280 5156 5008 4997>, <45554 57048 14280 5156 5008 4997>;
			};
		};
	};
};

&soc {
	/delete-node/ ssphy@88e8000;

	xiaomi_touch {
		compatible = "xiaomi-touch";
		status = "ok";
		touch,name = "xiaomi-touch";
	};

	/* FROM-4.14 (dt/414/xiaomi/sweet/sweet-sdmmagpie.dtsi): target only, 4.14 bindings, check */
	fingerprint_fortsense {
		compatible = "fs,fingerprint";
		fs,gpio-reset = <&tlmm 58 0x0>;
		fs,gpio-irq = <&tlmm 57 0x0>;
		fs_vdd-supply = <&L7C>;
		status = "ok";
	};

	/* FROM-4.14 (dt/414/xiaomi/sweet/sweet-sdmmagpie.dtsi): target only, 4.14 bindings, check */
	fingerprint_fpc {
		status = "ok";
		compatible = "fpc,fpc1020";
		interrupt-parent = <&tlmm>;
		interrupts = <57 0x0>;
		fpc,gpio_rst = <&tlmm 58 0x0>;
		fpc,gpio_irq = <&tlmm 57 0x0>;
		fp_vdd_vreg-supply = <&L7C>;
		pinctrl-names = "fpc1020_reset_reset",
			"fpc1020_reset_active",
			"fpc1020_irq_active";
		pinctrl-0 = <&msm_gpio_58>;
		pinctrl-1 = <&msm_gpio_58_output_high>;
		pinctrl-2 = <&msm_gpio_57>;
	};

	/* FROM-4.14 (dt/414/xiaomi/sweet/sweet-sdmmagpie.dtsi): target only, 4.14 bindings, check */
	onewire_gpio: onewire_gpio {
		compatible = "xiaomi,onewire_gpio";
		label = "xm_onewire";
		xiaomi,version = <1>;
		xiaomi,ow_gpio = <&tlmm 91 0x00>;
		mi,onewire-gpio-cfg-addr = <0x0395B000 0x4>;
		pinctrl-names = "onewire_active", "onewire_sleep";
		pinctrl-0 = <&onewire_gpio_active>;
		pinctrl-1 = <&onewire_gpio_sleep>;
		status = "ok";
	};

	/* FROM-4.14 (dt/414/xiaomi/sweet/sweet-sdmmagpie.dtsi): target only, 4.14 bindings, check */
	maxim_ds28e16: maxim_ds28e16 {
		compatible = "maxim,ds28e16";
		label = "max_ds28e16";
		maxim,version = <1>;
		status = "ok";
	};

	/* FROM-4.14 (dt/414/xiaomi/sweet/sweet-sdmmagpie.dtsi): target only, 4.14 bindings, check */
	cp_qc30 {
		compatible = "xiaomi,cp-qc30";
		status = "ok";
		mi,qc3-bat-volt-max = <4450>;
		mi,qc3-ffc-bat-volt-max = <4470>;
		mi,qc3-bat-curr-max = <5400>;
		mi,qc3-bus-volt-max = <12000>;
		mi,qc3-bus-curr-max = <2100>;
		mi,support-qc3p5-without-smb;
	};

	/* FROM-4.14 (dt/414/xiaomi/sweet/sweet-sdmmagpie.dtsi): target only, 4.14 bindings, check */
	usbpd_pm {
		compatible = "xiaomi,usbpd-pm";
		status = "ok";
		mi,pd-bat-volt-max = <4450>;
		mi,pd-ffc-bat-volt-max = <4470>;
		mi,pd-bat-curr-max = <6000>;
		mi,pd-bus-volt-max = <12000>;
		mi,pd-bus-curr-max = <3000>;
		mi,pd-bus-curr-compensate = <100>;
	};

	/* FROM-4.14 (dt/414/xiaomi/sweet/sweet-sdmmagpie.dtsi): target only, 4.14 bindings, check */
	simtray {
		compatible = "xiaomi,simtray-status";
		status-gpio = <&tlmm 82 0x00>;
	};

	/* FROM-4.14 (dt/414/xiaomi/sweet/sweet-sdmmagpie.dtsi): target only, 4.14 bindings, check */
	thermal_message: thermal-message {
		board-sensor = "VIRTUAL-SENSOR";
	};

	/* FROM-4.14 (dt/414/xiaomi/sweet/sweet-sdmmagpie.dtsi): target only, 4.14 bindings, check */
	irda_regulator: irda-regulator {
		compatible = "regulator-dummy";
		regulator-name = "irda_regulator";
	};
};

&spmi_bus {

	qcom,pm6150l@5 {
	};

	qcom,pm6150l@4 {
	};
};

&pm6150_vadc {

	pa_therm0 {
		reg = <ADC5_AMUX_THM2_100K_PU>;
		label = "pa_therm0";
		qcom,ratiometric;
		qcom,hw-settle-time = <200>;
		qcom,pre-scaling = <1 1>;
	};

	cpu_therm {
		reg = <ADC5_AMUX_THM3_100K_PU>;
		label = "cpu_therm";
		qcom,ratiometric;
		qcom,hw-settle-time = <200>;
		qcom,pre-scaling = <1 1>;
	};

	quiet_therm {
		reg = <ADC5_AMUX_THM4_100K_PU>;
		label = "quiet_therm";
		qcom,ratiometric;
		qcom,hw-settle-time = <200>;
		qcom,pre-scaling = <1 1>;
	};
};

&pm6150_charger {
	/* MERGE io-channels: 4.14 target has <&pm6150_vadc ADC5_USB_IN_V_16>, <&pm6150_vadc ADC5_USB_IN_I>, <&pm6150_vadc ADC5_CHG_TEMP>, <&pm6150_vadc ADC5_DIE_TEMP>, <&pm6150l_vadc ADC5_AMUX_THM1_100K_PU>, <&pm6150_vadc ADC_SBUx>, <&pm6150_vadc ADC5_VPH_PWR> */
	/* MERGE io-channel-names: 4.14 target has "usb_in_voltage",
			   "usb_in_current",
			   "chg_temp",
			   "die_temp",
			   "conn_temp",
			   "sbux_res",
			   "vph_voltage" */
	io-channels = <&pm6150_vadc ADC5_USB_IN_V_16>, <&pm6150_vadc ADC5_USB_IN_I>, <&pm6150_vadc ADC5_CHG_TEMP>, <&pm6150_vadc ADC5_DIE_TEMP>, <&pm6150l_vadc ADC5_AMUX_THM1_100K_PU>, <&pm6150_vadc ADC5_SBUx>, <&pm6150_vadc ADC5_VPH_PWR>, <&pm6150_qg PSY_IIO_RESISTANCE_ID>, <&pm6150_qg PSY_IIO_VOLTAGE_NOW>, <&pm6150_qg PSY_IIO_TEMP>, <&pm6150_qg PSY_IIO_CAPACITY>, <&pm6150_qg PSY_IIO_VOLTAGE_OCV>, <&pm6150_qg PSY_IIO_VOLTAGE_AVG>, <&pm6150_qg PSY_IIO_DEBUG_BATTERY>, <&pm6150_qg PSY_IIO_REAL_CAPACITY>, <&pm6150_qg PSY_IIO_CC_SOC>, <&pm6150_qg PSY_IIO_CURRENT_NOW>, <&pm6150_qg PSY_IIO_VOLTAGE_MAX>, <&pm6150_qg PSY_IIO_CHARGE_FULL>, <&pm6150_qg PSY_IIO_CHARGE_COUNTER>, <&pm6150_qg PSY_IIO_CYCLE_COUNT>, <&pm6150_qg PSY_IIO_CHARGE_FULL_DESIGN>, <&pm6150_qg PSY_IIO_TIME_TO_FULL_NOW>;
	io-channel-names = "usb_in_voltage", "usb_in_current", "chg_temp", "die_temp", "conn_temp", "sbux_res", "vph_voltage", "resistance_id", "voltage_now", "temp", "capacity", "voltage_ocv", "voltage_avg", "debug_battery", "real_capacity", "cc_soc", "current_now", "voltage_max", "charge_full", "charge_counter", "cycle_count", "charge_full_design", "time_to_full_now";
	qcom,battery-data = <&mtp_batterydata>;
	dpdm-supply = <&qusb_phy0>;
	qcom,sec-charger-config = <0>;
	qcom,chg-term-src = <1>;
	qcom,chg-term-current-ma = <(-200)>;
	qcom,auto-recharge-soc = <99>;
	qcom,sw-jeita-enable;
	qcom,thermal-mitigation = <6000000 5000000 4500000 4000000 3500000 3000000 2900000 2800000 2600000 2400000 2200000 2000000 1800000 1500000 1000000 500000>;
	qcom,thermal-mitigation-icl = <3000000 3000000 3000000 2400000 2200000 2100000 2000000 2000000 2000000 1900000 1800000 1600000 1500000 1300000 1300000 750000>;
	qcom,thermal-mitigation-dcp = <1800000 1800000 1800000 1800000 1800000 1800000 1800000 1800000 1800000 1700000 1600000 1400000 1200000 1100000 1100000 1000000>;
	qcom,thermal-mitigation-qc2 = <1500000 1500000 1500000 1500000 1450000 1400000 1350000 1300000 1150000 1100000 1000000 900000 850000 750000 650000 500000>;
	qcom,thermal-fcc-qc3-normal = <6000000 5000000 4500000 4000000 3500000 3000000 2900000 2800000 2700000 2600000 2400000 2200000 2000000 2000000 750000 700000>;
	qcom,thermal-mitigation-pd-base = <6000000 5000000 4500000 4000000 3400000 3300000 3200000 3100000 3000000 2800000 2600000 2400000 2200000 2000000 1000000 700000>;
	qcom,usb-icl-ua = <3000000>;
	qcom,fcc-max-ua = <6000000>;
	mi,fcc-batt-unverify-ua = <2000000>;
	qcom,fv-max-uv = <4470000>;
	qcom,reg-dump-enable;
	qcom,distinguish-qc-class-ab;
	qcom,lpd-disable;
	qcom,usbpd-phandle = <&pm6150_pdphy>;
	qcom,disable-suspend-on-collapse;
	mi,use-bq-pump;
	mi,support-ffc;
	mi,early-status-report;
	mi,support-qc3p5-without-smb;
	mi,ffc-low-tbat = <150>;
	mi,ffc-high-tbat = <480>;
	qcom,thermal-fcc-qc3-cp = <6000000 5000000 4500000 4000000 3500000 3300000 3200000 3100000 3000000 2800000 2600000 2400000 2200000 2000000 2000000 200000>;
	qcom,thermal-fcc-pps-cp = <6000000 5500000 5000000 4500000 4100000 3900000 3500000 3200000 3100000 2800000 2600000 2400000 2200000 2000000 1000000 700000>;
};

&pm6150_pdphy {
	mi,non-qcom-pps-ctrl;
	mi,pd_curr_limit = <1>;
	mi,pd_max_curr_limit = <4000000>;
	mi,limit_pd_unverified_pps_vbus = <1>;
	mi,pd_unverified_pps_max_vbus_limit = <9500000>;
};

&pm6150_qg {
	qcom,vbatt-low-mv = <3500>;
	qcom,vbatt-low-cold-mv = <3800>;
	qcom,vbatt-empty-cold-mv = <3000>;
	qcom,battery-data = <&mtp_batterydata>;
	qcom,qg-iterm-ma = <350>;
	qcom,s3-entry-ibat-ua = <25000>;
	qcom,s3-exit-ibat-ua = <45000>;
	qcom,hold-soc-while-full;
	qcom,linearize-soc;
	qcom,cl-feedback-on;
	qcom,shutdown-soc-threshold = <10>;
	qcom,qg-ext-sns;
	mi,software-optimize-ffc-qg-iterm;
	qcom,shutdown-delay-enable;
	qcom,tcss-enable;
	qcom,tcss-entry-soc = <90>;
	qcom,bass-enable;
	qcom,soc_decimal_rate = < 0 32 10 30 20 28 30 28 40 28 50 28 60 28 70 28 80 28 90 26 95 10 99 5>;
};

&pm6150_adc_tm {
	/* board ADC-TM channels: 4.14 board file in the 6.1 ADC-TM5 form */
	status = "okay";

	xo-therm@0 {
		reg = <0>;
		io-channels = <&pm6150_vadc ADC5_XO_THERM_100K_PU>;
		qcom,ratiometric;
		qcom,hw-settle-time-us = <200>;
	};

	pa-therm0@1 {
		reg = <1>;
		io-channels = <&pm6150_vadc ADC5_AMUX_THM2_100K_PU>;
		qcom,ratiometric;
		qcom,hw-settle-time-us = <200>;
	};

	cpu-therm@2 {
		reg = <2>;
		io-channels = <&pm6150_vadc ADC5_AMUX_THM3_100K_PU>;
		qcom,ratiometric;
		qcom,hw-settle-time-us = <200>;
	};

	quiet-therm@3 {
		reg = <3>;
		io-channels = <&pm6150_vadc ADC5_AMUX_THM4_100K_PU>;
		qcom,ratiometric;
		qcom,hw-settle-time-us = <200>;
	};
};

&pm6150l_lcdb {
	status = "disabled";
};

&pm6150l_wled {
	status = "disabled";
};

&pm6150l_vadc {

	conn_therm {
		reg = <ADC5_AMUX_THM1_100K_PU>;
		label = "conn_therm";
		qcom,ratiometric;
		qcom,hw-settle-time = <200>;
		qcom,pre-scaling = <1 1>;
	};

	charger_therm0 {
		reg = <ADC5_AMUX_THM2_100K_PU>;
		label = "charger_therm0";
		qcom,ratiometric;
		qcom,hw-settle-time = <200>;
		qcom,pre-scaling = <1 1>;
	};

	smb_therm {
		reg = <ADC5_AMUX_THM2>;
		label = "smb_therm";
		qcom,hw-settle-time = <200>;
		qcom,pre-scaling = <1 1>;
	};

	wifi_therm {
		reg = <ADC5_AMUX_THM3_100K_PU>;
		label = "wifi_therm";
		qcom,ratiometric;
		qcom,hw-settle-time = <200>;
		qcom,pre-scaling = <1 1>;
	};

	nvm_therm {
		reg = <ADC5_GPIO4_100K_PU>;
		label = "nvm_therm";
		qcom,ratiometric;
		qcom,hw-settle-time = <200>;
		qcom,pre-scaling = <1 1>;
	};
};

&pm6150l_adc_tm {
	/* board ADC-TM channels: 4.14 board file in the 6.1 ADC-TM5 form */
	status = "okay";

	conn-therm@0 {
		reg = <0>;
		io-channels = <&pm6150l_vadc ADC5_AMUX_THM1_100K_PU>;
		qcom,ratiometric;
		qcom,hw-settle-time-us = <200>;
	};

	charger-therm0@1 {
		reg = <1>;
		io-channels = <&pm6150l_vadc ADC5_AMUX_THM2_100K_PU>;
		qcom,ratiometric;
		qcom,hw-settle-time-us = <200>;
	};

	wifi-therm@2 {
		reg = <2>;
		io-channels = <&pm6150l_vadc ADC5_AMUX_THM3_100K_PU>;
		qcom,ratiometric;
		qcom,hw-settle-time-us = <200>;
	};

	nvm-therm@3 {
		reg = <3>;
		io-channels = <&pm6150l_vadc ADC5_GPIO4_100K_PU>;
		qcom,ratiometric;
		qcom,hw-settle-time-us = <200>;
	};
};

&pm6150l_gpios {

	/* FROM-4.14 (dt/414/xiaomi/sweet/sweet-sdmmagpie-pinctrl.dtsi): target only, 4.14 bindings, check */
	aw8624_interrupt_pin {

		/* FROM-4.14 (dt/414/xiaomi/sweet/sweet-sdmmagpie-pinctrl.dtsi): target only, 4.14 bindings, check */
		aw8624_interrupt_pin: aw8624_interrupt_pin {
			pins = "gpio10";
			function = "normal";
			bias-pull-up;
			input-enable;
			power-source = <1>;
			qcom,pull-up-strength = <2>;
		};
	};
};

&thermal_zones {

	/* board thermistor zone, 4.14 name and trips */
	xo_therm {
		polling-delay-passive = <0>;
		polling-delay = <0>;
		thermal-sensors = <&pm6150_adc_tm 0>;

		trips {

			active-config0 {
				temperature = <125000>;
				hysteresis = <1000>;
				type = "passive";
			};
		};
	};

	/* board thermistor zone, 4.14 name and trips */
	pa_therm0 {
		polling-delay-passive = <0>;
		polling-delay = <0>;
		thermal-sensors = <&pm6150_adc_tm 1>;

		trips {

			active-config0 {
				temperature = <125000>;
				hysteresis = <1000>;
				type = "passive";
			};
		};
	};

	/* board thermistor zone, 4.14 name and trips */
	cpu_therm {
		polling-delay-passive = <0>;
		polling-delay = <0>;
		thermal-sensors = <&pm6150_adc_tm 2>;

		trips {

			active-config0 {
				temperature = <125000>;
				hysteresis = <1000>;
				type = "passive";
			};
		};
	};

	/* board thermistor zone, 4.14 name and trips */
	quiet_therm {
		polling-delay-passive = <0>;
		polling-delay = <0>;
		thermal-sensors = <&pm6150_adc_tm 3>;

		trips {

			active-config0 {
				temperature = <125000>;
				hysteresis = <1000>;
				type = "passive";
			};
		};
	};

	/* board thermistor zone, 4.14 name and trips */
	conn_therm {
		polling-delay-passive = <0>;
		polling-delay = <0>;
		thermal-sensors = <&pm6150l_adc_tm 0>;

		trips {

			active-config0 {
				temperature = <125000>;
				hysteresis = <1000>;
				type = "passive";
			};
		};
	};

	/* board thermistor zone, 4.14 name and trips */
	charger_therm0 {
		polling-delay-passive = <0>;
		polling-delay = <0>;
		thermal-sensors = <&pm6150l_adc_tm 1>;

		trips {

			active-config0 {
				temperature = <125000>;
				hysteresis = <1000>;
				type = "passive";
			};
		};
	};

	/* board thermistor zone, 4.14 name and trips */
	wifi_therm {
		polling-delay-passive = <0>;
		polling-delay = <0>;
		thermal-sensors = <&pm6150l_adc_tm 2>;

		trips {

			active-config0 {
				temperature = <125000>;
				hysteresis = <1000>;
				type = "passive";
			};
		};
	};
};

&ufshc_mem {
	vccq2-voltage-level = <1800000 1950000>;
	rpm-level = <3>;
};

&qcom_smcinvoke {
	reg = <0x86d00000 0x3E00000>;
};

&tlmm {

	nfc {
	};

	pmx_ts_active {

		tp_active: tp_active {

			mux {
				pins = "gpio9", "gpio8";
				function = "gpio";
			};

			config {
				pins = "gpio9", "gpio8";
				drive-strength = <16>;
				bias-pull-up;
			};
		};
	};

	pmx_ts_int_suspend {

		tp_int_suspend: tp_int_suspend {

			mux {
				pins = "gpio9";
				function = "gpio";
			};

			config {
				pins = "gpio9";
				drive-strength = <16>;
				input-enable;
				slew-rate = <0>;
				bias-pull-up = <00>;
			};
		};
	};

	pmx_ts_reset_suspend {

		tp_reset_suspend: tp_reset_suspend {

			mux {
				pins = "gpio8";
				function = "gpio";
			};

			config {
				pins = "gpio8";
				drive-strength = <16>;
				slew-rate = <1>;
				bias-disable;
				output-high;
			};
		};
	};

	bq2597x {

		bq2597x_int_default: bq2597x_int_default {

			mux {
				pins = "gpio55";
				function = "gpio";
			};

			config {
				pins = "gpio55";
				drive-strength = <2>;
				bias-pull-up;
				input-enable;
			};
		};

		bq2597x_int_suspend: bq2597x_int_suspend {

			mux {
				pins = "gpio55";
				function = "gpio";
			};

			config {
				pins = "gpio55";
				drive-strength = <2>;
				bias-pull-up;
				input-enable;
			};
		};
	};

	onewire_gpio_active: onewire_gpio_active {

		mux {
			pins = "gpio91";
			function = "gpio";
		};

		config {
			pins = "gpio91";
			drive-strength = <2>;
			bias-pull-up;
		};
	};

	onewire_gpio_sleep: onewire_gpio_sleep {

		mux {
			pins = "gpio91";
			function = "gpio";
		};

		config {
			pins = "gpio91";
			drive-strength = <2>;
			bias-pull-up;
		};
	};

	top_smartpa_int_active: top_smartpa_int_active {

		mux {
			pins = "gpio93";
			function = "gpio";
		};

		config {
			pins = "gpio93";
			drive-strength = <2>;
			bias-pull-up;
			input-enable;
		};
	};

	top_smartpa_int_suspend: top_smartpa_int_suspend {

		mux {
			pins = "gpio93";
			function = "gpio";
		};

		config {
			pins = "gpio93";
			drive-strength = <2>;
			bias-pull-up;
			input-enable;
		};
	};

	bot_smartpa_int_active: bot_smartpa_int_active {

		mux {
			pins = "gpio56";
			function = "gpio";
		};

		config {
			pins = "gpio56";
			drive-strength = <2>;
			bias-pull-up;
			input-enable;
		};
	};

	bot_smartpa_int_suspend: bot_smartpa_int_suspend {

		mux {
			pins = "gpio56";
			function = "gpio";
		};

		config {
			pins = "gpio56";
			drive-strength = <2>;
			bias-pull-up;
			input-enable;
		};
	};

	aw8624_gpio_reset: aw8624_gpio_reset {

		mux {
			pins = "gpio4";
			function = "gpio";
		};

		config {
			pins = "gpio4";
			drive-strength = <2>;
			bias-disable;
			output-low;
		};
	};

	aw8624_gpio_reset_output_high: aw8624_gpio_reset_output_high {

		mux {
			pins = "gpio4";
			function = "gpio";
		};

		config {
			pins = "gpio4";
			drive-strength = <2>;
			bias-disable;
			output-high;
		};
	};

	cam_sensor_wide_active: cam_sensor_wide_active {

		mux {
			pins = "gpio26";
			function = "gpio";
		};

		config {
			pins = "gpio26";
			bias-disable;
			drive-strength = <2>;
		};
	};

	cam_sensor_wide_suspend: cam_sensor_wide_suspend {

		mux {
			pins = "gpio26";
			function = "gpio";
		};

		config {
			pins = "gpio26";
			bias-pull-down;
			drive-strength = <2>;
			output-low;
		};
	};

	cam_sensor_front_active: cam_sensor_front_active {

		mux {
			pins = "gpio23";
			function = "gpio";
		};

		config {
			pins = "gpio23";
			bias-disable;
			drive-strength = <2>;
		};
	};

	cam_sensor_front_suspend: cam_sensor_front_suspend {

		mux {
			pins = "gpio23";
			function = "gpio";
		};

		config {
			pins = "gpio23";
			bias-pull-down;
			drive-strength = <2>;
			output-low;
		};
	};

	cam_sensor_macro_active: cam_sensor_macro_active {

		mux {
			pins = "gpio24";
			function = "gpio";
		};

		config {
			pins = "gpio24";
			bias-disable;
			drive-strength = <2>;
		};
	};

	cam_sensor_macro_suspend: cam_sensor_macro_suspend {

		mux {
			pins = "gpio24";
			function = "gpio";
		};

		config {
			pins = "gpio24";
			bias-pull-down;
			drive-strength = <2>;
			output-low;
		};
	};

	cam_sensor_depth_active: cam_sensor_depth_active {

		mux {
			pins = "gpio21";
			function = "gpio";
		};

		config {
			pins = "gpio21";
			bias-disable;
			drive-strength = <2>;
		};
	};

	cam_sensor_depth_suspend: cam_sensor_depth_suspend {

		mux {
			pins = "gpio21";
			function = "gpio";
		};

		config {
			pins = "gpio21";
			bias-pull-down;
			drive-strength = <2>;
			output-low;
		};
	};

	cam_sensor_ultra_active: cam_sensor_ultra_active {

		mux {
			pins = "gpio25";
			function = "gpio";
		};

		config {
			pins = "gpio25";
			bias-disable;
			drive-strength = <2>;
		};
	};

	cam_sensor_ultra_suspend: cam_sensor_ultra_suspend {

		mux {
			pins = "gpio25";
			function = "gpio";
		};

		config {
			pins = "gpio25";
			bias-pull-down;
			drive-strength = <2>;
			output-low;
		};
	};

	cam_sensor_vddio_enable: cam_sensor_vddio_enable {

		mux {
			pins = "gpio5";
			function = "gpio";
		};

		config {
			pins = "gpio5";
			bias-disable;
			drive-strength = <2>;
		};
	};

	cam_sensor_vddio_disable: cam_sensor_vddio_disable {

		mux {
			pins = "gpio5";
			function = "gpio";
		};

		config {
			pins = "gpio5";
			bias-pull-down;
			drive-strength = <2>;
			output-low;
		};
	};

	cam_sensor_f_vdda_f_vddd_enable: cam_sensor_f_vdda_f_vddd_enable {

		mux {
			pins = "gpio57";
			function = "gpio";
		};

		config {
			pins = "gpio57";
			bias-disable;
			drive-strength = <2>;
		};
	};

	cam_sensor_f_vdda_f_vddd_disable: cam_sensor_f_vdda_f_vddd_disable {

		mux {
			pins = "gpio57";
			function = "gpio";
		};

		config {
			pins = "gpio57";
			bias-pull-down;
			drive-strength = <2>;
			output-low;
		};
	};

	cam_sensor_mipi_switch_sel_low: cam_sensor_mipi_switch_sel_low {

		mux {
			pins = "gpio88";
			function = "gpio";
		};

		config {
			pins = "gpio88";
			bias-disable;
			drive-strength = <2>;
		};
	};

	cam_sensor_mipi_switch_sel_high: cam_sensor_mipi_switch_sel_high {

		mux {
			pins = "gpio88";
			function = "gpio";
		};

		config {
			pins = "gpio88";
			bias-disable;
			drive-strength = <2>;
			output-low;
		};
	};

	cam_sensor_mipi_switch1_sel_low: cam_sensor_mipi_switch1_sel_low {

		mux {
			pins = "gpio90";
			function = "gpio";
		};

		config {
			pins = "gpio90";
			bias-disable;
			drive-strength = <2>;
		};
	};

	cam_sensor_mipi_switch1_sel_high: cam_sensor_mipi_switch1_sel_high {

		mux {
			pins = "gpio90";
			function = "gpio";
		};

		config {
			pins = "gpio90";
			bias-disable;
			drive-strength = <2>;
			output-low;
		};
	};

	msm_gpio_58: msm_gpio_58 {

		mux {
			pins = "gpio58";
			function = "gpio";
		};

		config {
			pins = "gpio58";
			driver-strength = <2>;
			bias-disable;
			output-low;
		};
	};

	msm_gpio_58_output_high: msm_gpio_24_output_high {

		mux {
			pins = "gpio58";
			function = "gpio";
		};

		config {
			pins = "gpio58";
			drive-strength = <2>;
			bias-disable;
			output-high;
		};
	};

	msm_gpio_57: msm_gpio_57 {

		mux {
			pins = "gpio57";
			function = "gpio";
		};

		config {
			pins = "gpio57";
			drive-strength = <2>;
			bias-pull-down;
		};
	};
};

&nfc_enable_active {

	mux {
		pins = "gpio66", "gpio36";
	};

	config {
		pins = "gpio66", "gpio36";
	};
};

&nfc_enable_suspend {

	mux {
		pins = "gpio66", "gpio36";
	};

	config {
		pins = "gpio66", "gpio36";
	};
};

&cam_sensor_mclk0_active {

	config {
		drive-strength = <6>;
	};
};

&cam_sensor_mclk0_suspend {

	config {
		drive-strength = <6>;
	};
};

&cam_sensor_mclk1_active {

	config {
		drive-strength = <4>;
	};
};

&cam_sensor_mclk1_suspend {

	config {
		drive-strength = <4>;
	};
};

&cam_sensor_mclk2_active {

	config {
		drive-strength = <4>;
	};
};

&cam_sensor_mclk2_suspend {

	config {
		drive-strength = <4>;
	};
};

&cam_sensor_mclk3_active {

	config {
		drive-strength = <4>;
	};
};

&cam_sensor_mclk3_suspend {

	config {
		drive-strength = <4>;
	};
};

&usb0 {

	dwc3@a600000 {
		usb-phy = <&qusb_phy0>, <&usb_nop_phy>;
		maximum-speed = "high-speed";
	};
};

&qusb_phy0 {
	qcom,qusb-phy-init-seq = <0x23 0x210 0x03 0x04 0x7c 0x18c 0x80 0x2c 0x0a 0x184 0x19 0xb4 0x40 0x194 0x16 0x198 0x21 0x214 0x08 0x220 0x58 0x224 0x07 0x240 0x29 0x244 0xca 0x248 0x07 0x24c 0x03 0x250 0x30 0x23c 0x22 0x210>;
};

&qupv3_se2_i2c {
	status = "ok";
	qcom,clk-freq-out = <1000000>;

	nq@28 {
		compatible = "qcom,nq-nci";
		reg = <0x28>;
		qcom,nq-irq = <&tlmm 37 0x00>;
		qcom,nq-ven = <&tlmm 66 0x00>;
		qcom,nq-firm = <&tlmm 36 0x00>;
		qcom,nq-clkreq = <&tlmm 31 0x00>;
		interrupt-parent = <&tlmm>;
		interrupts = <37 0>;
		interrupt-names = "nfc_irq";
		pinctrl-names = "nfc_active", "nfc_suspend";
		pinctrl-0 = <&nfc_int_active &nfc_enable_active &nfc_clk_req_active>;
		pinctrl-1 = <&nfc_int_suspend &nfc_enable_suspend &nfc_clk_req_suspend>;
	};
};

&qupv3_se4_i2c {
	status = "ok";

	aw882xx_smartpa@34 {
		compatible = "awinic,aw882xx_smartpa";
		reg = <0x34>;
		reset-gpio = <&tlmm 64 0>;
		irq-gpio = <&tlmm 93 0>;
		interrupt-parent = <&tlmm>;
		interrupts = <93 0>;
		interrupt-names = "smartpa_irq";
		pinctrl-names = "default", "sleep";
		pinctrl-0 = <&top_smartpa_int_active>;
		pinctrl-1 = <&top_smartpa_int_suspend>;
		monitor-flag = <1>;
		aw-cali-mode = "aw_class";
		sound-channel = <0>;
		status = "ok";
	};

	aw882xx_smartpa@35 {
		compatible = "awinic,aw882xx_smartpa";
		reg = <0x35>;
		reset-gpio = <&tlmm 72 0>;
		irq-gpio = <&tlmm 56 0>;
		interrupt-parent = <&tlmm>;
		interrupts = <56 0>;
		interrupt-names = "smartpa_irq";
		pinctrl-names = "default", "sleep";
		pinctrl-0 = <&bot_smartpa_int_active>;
		pinctrl-1 = <&bot_smartpa_int_suspend>;
		monitor-flag = <1>;
		aw-cali-mode = "aw_class";
		sound-channel = <1>;
		status = "ok";
	};
};

&qupv3_se7_i2c {
	status = "ok";

	gt9896@5d {
		compatible = "goodix,gt9896";
		reg = <0x5d>;
		status = "ok";
		interrupt-parent = <&tlmm>;
		interrupts = <9 0x0>;
		pinctrl-names = "pmx_ts_active", "pmx_ts_suspend";
		pinctrl-0 = <&ts_active>;
		pinctrl-1 = <&ts_int_suspend &ts_reset_suspend>;
		vtouch-supply = <&pm6150l_l11>;
		goodix,vdd-gpio = <&tlmm 90 0x0>;
		goodix,avdd-name = "vtouch";
		goodix,reset-gpio = <&tlmm 8 0x0>;
		goodix,irq-gpio = <&tlmm 9 0x0>;
		goodix,irq-flags = <2>;
		goodix,panel-max-id = <10>;
		goodix,panel-max-x = <1079>;
		goodix,panel-max-y = <2399>;
		goodix,panel-max-w = <256>;
		goodix,panel-max-p = <256>;
		goodix,input-max-x = <1079>;
		goodix,input-max-y = <2399>;
		goodix,power-on-delay-us = <100>;
		goodix,power-off-delay-us = <5000>;
		goodix,firmware-version = "6885b1";
		goodix,config-version = "6885v9c";
		tpd-filter-enable = <1>;
		tpd-filter-pixel-density = <161>;
		tpd-filter-custom-prameters = <0 0 0 0 0 0 0 0 0 0 0 0>;
		tpd-filter-custom-speed = <0 0 0>;
		goodix,touch-game-param-config1 = <3 3 1 3>;
		goodix,touch-game-param-config2 = <2 4 2 3>;
		goodix,touch-game-param-config3 = <4 4 3 1>;

		sensor0 {
			normal-cfg = [ ];
		};
	};

	focaltech@38 {
		compatible = "focaltech,fts_K6";
		reg = <0x38>;
		interrupt-parent = <&tlmm>;
		interrupts = <9 0x0>;
		vdd-supply = <&pm6150l_l11>;
		vcc_i2c-supply = <&tlmm 90 0x00>;
		focaltech,reset-gpio = <&tlmm 8 0x00>;
		focaltech,irq-gpio = <&tlmm 9 0x00>;
		focaltech,max-touch-number = <10>;
		focaltech,display-coords = <0 0 1079 2399>;
		pinctrl-names = "pmx_ts_active", "pmx_ts_suspend", "pmx_ts_release";
		pinctrl-0 = <&ts_active>;
		pinctrl-1 = <&ts_int_suspend &ts_reset_suspend>;
		pinctrl-2 = <&ts_release>;
		focaltech,touch-range-array = <1 5 10 15 20>;
		focaltech,touch-def-array = <3 3 3 3>;
		focaltech,touch-expert-array = <10 10 10 10 20 20 15 10 20 20 20 10>;
	};
};

&qupv3_se9_i2c {
	status = "ok";
	qcom,clk-freq-out = <400000>;
	qcom,clk-freq-in = <400000>;

	bq25970-standalone@66 {
		compatible = "ti,bq2597x-standalone";
		reg = <0x66>;
		interrupt-parent = <&tlmm>;
		interrupts = <55 0x2002>;
		pinctrl-names = "default";
		pinctrl-0 = <&bq2597x_int_default &bq2597x_int_suspend>;
		ti,bq2597x,bat-ovp-alarm-disable;
		ti,bq2597x,bat-ocp-disable;
		ti,bq2597x,bat-ocp-alarm-disable;
		ti,bq2597x,bat-ucp-alarm-disable;
		ti,bq2597x,bat-ucp-disable;
		ti,bq2597x,bat-therm-disable;
		ti,bq2597x,bus-therm-disable;
		ti,bq2597x,die-therm-disable;
		ti,bq2597x,bat-ovp-threshold = <4550>;
		ti,bq2597x,bat-ovp-alarm-threshold = <4525>;
		ti,bq2597x,bus-ovp-threshold = <12000>;
		ti,bq2597x,bus-ovp-alarm-threshold = <11000>;
		ti,bq2597x,bus-ocp-threshold = <3750>;
		ti,bq2597x,bus-ocp-alarm-threshold = <3500>;
		ti,bq2597x,bat-therm-threshold = <0x15>;
		ti,bq2597x,bus-therm-threshold = <0x15>;
		ti,bq2597x,die-therm-threshold = <145>;
		ti,bq2597x,ac-ovp-threshold = <14>;
	};

	aw8624_haptic@5A {
		compatible = "awinic,aw8624_haptic";
		reg = <0x5A>;
		reset-gpio = <&tlmm 4 0>;
		irq-gpio = <&pm6150l_gpios  10 0>;
		vib_f0_pre = < 2050 >;
		vib_f0_cali_percen = < 7 >;
		vib_cont_drv_lev = < 106 >;
		vib_cont_drv_lvl_ov = < 155 >;
		vib_cont_td = < 0xF06C >;
		vib_cont_zc_thr = < 0x08F8 >;
		vib_cont_num_brk = < 3 >;
		vib_f0_coeff = < 260 >;
		vib_duration_time = < 15 60 0 0 0 >;
		vib_brake_ram_config = < 1 1 90 60 20 3 1 3 1 1 90 60 30 5 1 3 0 0 50 40 25 0 5 3 >;
		vib_brake_cont_config = < 1 1 90 42 20 5 2 2 0 0 0 0 0 0 0 0 0 0 0 0 0 0 0 0 >;
		vib_f0_trace_parameter = < 9 5 1 15 >;
		vib_bemf_config = < 0 8 3 0xf8 >;
		vib_sw_brake = < 0x2c >;
		vib_wavseq = < 0 1 1 2 0 0 0 0 0 0 0 0 0 0 0 0 >;
		vib_wavloop = < 0 6 1 15 0 0 0 0 0 0>;
		vib_td_brake = < 42720 42720 42720 >;
		vib_tset = < 0x11 >;
		vib_func_parameter1 = < 1 >;
		vib_gain_flag = < 1 >;
		vib_r_spare = < 0x68 >;
		vib_bstdbg = < 0x30 0xeb 0xd4 0 0 0 >;
		vib_effect_id_boundary = < 10 >;
		vib_effect_max = < 170 >;
		vib_rtp_time = < 20 20 20 20 20 20 20 20 20 30 40 50 60 70 80 90 100 110 120 130 140 150 160 170 180 190 200 210 220 230 240 250 260 270 280 290 300 310 320 330 20 20 20 20 20 20 20 20 20 20 20 20 20 20 20 20 20 20 20 20 20 20 20 20 20 20 20 20 20 20 20 20 20 20 20 20 20 20 20 20 20 20 20 20 20 20 20 20 20 20 20 20 20 20 20 20 20 20 20 20 20 20 20 20 20 20 20 20 20 20 20 20 20 20 20 20 20 20 20 20 20 20 20 20 20 20 20 20 20 20 20 20 20 20 20 20 20 20 20 20 20 20 20 20 20 20 20 20 20 20 20 20 20 20 20 20 20 20 20 20 20 20 20 20 20 20 20 20 20 20 20 20 20 20 20 >;
		pinctrl-names = "aw8624_reset_reset","aw8624_reset_active","aw8624_interrupt_active";
		pinctrl-0 = <&aw8624_gpio_reset>;
		pinctrl-1 = <&aw8624_gpio_reset_output_high>;
		pinctrl-2 = <&aw8624_interrupt_pin>;

		wf_0 {
			qcom,effect-id = <0>;
			qcom,wf-vmax-mv = <3600>;
			qcom,wf-pattern = [3e 3e];
			qcom,wf-brake-pattern = [02 01 00 00];
			qcom,wf-play-rate-us = <20000>;
		};

		wf_1 {
			qcom,effect-id = <1>;
			qcom,wf-vmax-mv = <3600>;
			qcom,wf-pattern = [7e 3e];
			qcom,wf-brake-pattern = [03 01 00 00];
			qcom,wf-play-rate-us = <20000>;
		};

		wf_2 {
			qcom,effect-id = <2>;
			qcom,wf-vmax-mv = <3600>;
			qcom,wf-pattern = [7e 3e];
			qcom,wf-brake-pattern = [02 01 00 00];
			qcom,wf-play-rate-us = <20000>;
		};

		wf_3 {
			qcom,effect-id = <3>;
			qcom,wf-vmax-mv = <3600>;
			qcom,wf-pattern = [3e 3e];
			qcom,wf-brake-pattern = [02 01 00 00];
			qcom,wf-play-rate-us = <20000>;
		};

		wf_4 {
			qcom,effect-id = <4>;
			qcom,wf-vmax-mv = <3600>;
			qcom,wf-pattern = [3e 3e];
			qcom,wf-brake-pattern = [02 01 00 00];
			qcom,wf-play-rate-us = <28000>;
		};

		wf_5 {
			qcom,effect-id = <5>;
			qcom,wf-vmax-mv = <3600>;
			qcom,wf-pattern = [7e 7e 7e];
			qcom,wf-brake-pattern = [03 03 01 00];
			qcom,wf-play-rate-us = <20000>;
		};

		wf_6 {
			qcom,effect-id = <6>;
			qcom,wf-vmax-mv = <3600>;
			qcom,wf-pattern = [3e 3e];
			qcom,wf-brake-pattern = [02 01 00 00];
			qcom,wf-play-rate-us = <20000>;
		};

		wf_7 {
			qcom,effect-id = <7>;
			qcom,wf-vmax-mv = <3600>;
			qcom,wf-pattern = [3e 3e];
			qcom,wf-brake-pattern = [02 01 00 00];
			qcom,wf-play-rate-us = <20000>;
		};

		wf_8 {
			qcom,effect-id = <8>;
			qcom,wf-vmax-mv = <3600>;
			qcom,wf-pattern = [3e 3e];
			qcom,wf-brake-pattern = [02 01 00 00];
			qcom,wf-play-rate-us = <20000>;
		};

		wf_9 {
			qcom,effect-id = <9>;
			qcom,wf-vmax-mv = <3600>;
			qcom,wf-pattern = [3e 3e];
			qcom,wf-brake-pattern = [02 01 00 00];
			qcom,wf-play-rate-us = <20000>;
		};
	};

	wl2866d@28 {
		compatible = "xiaomi,wl2866d";
		reg = <0x28>;
		vin1-supply = <&S8C>;
		vin1-voltage-level = <1350000  1350000>;
		vin2-supply = <&BOB>;
		vin2-voltage-level = <3300000  3300000>;
		en-gpio = <&tlmm 30 0>;
		status = "ok";
	};
};

&qupv3_se8_spi {
	status = "ok";

	irled@0 {
		compatible = "ir-spi-led";
		reg = <0x0>;
		power-supply = <&irda_regulator>;
		status = "ok";
		spi-max-frequency = <19200000>;
	};
};

&removed_region {
	reg = <0 0x86200000 0 0x4900000>;
};

#include "sdmmagpie-sde.dtsi"
#include "sdmmagpie-gpu.dtsi"
#include "sweet-display.dtsi"

/ {
	k61,dtbo-target = <&soc>;

	__symbols__ {
		soc = "/soc";
	};
};

